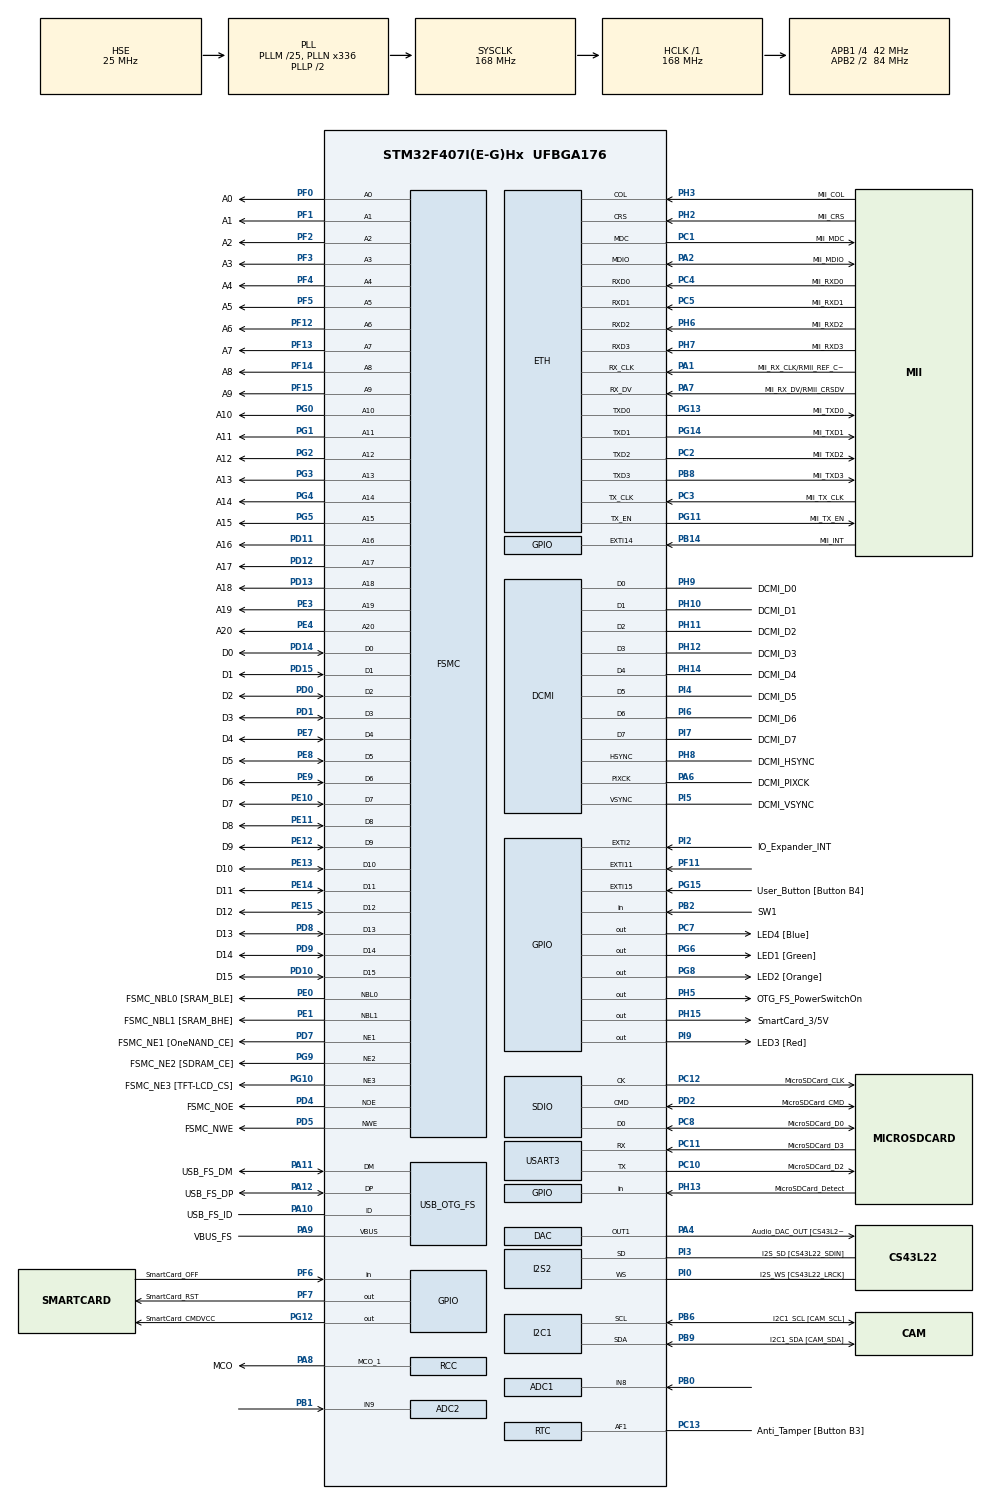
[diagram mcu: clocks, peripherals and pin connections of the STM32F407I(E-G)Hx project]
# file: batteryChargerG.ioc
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ADC1.Channel-0\#ChannelRegularConversion=ADC_CHANNEL_8
ADC1.Channel-4\#ChannelRegularConversion=ADC_CHANNEL_8
ADC1.ClockPrescaler=ADC_CLOCKPRESCALER_PCLK_DIV4
ADC1.ContinuousConvMode=ENABLE
ADC1.DMAContinuousRequests=ENABLE
ADC1.DataAlign=ADC_DATAALIGN_RIGHT
ADC1.DiscontinuousConvMode=DISABLE
ADC1.EOCSelection=EOC_SINGLE_CONV
ADC1.EnableAnalogWatchDog=false
ADC1.ExternalTrigConvEdge=ADC_EXTERNALTRIGCONVEDGE_NONE
ADC1.InjNumberOfConversion=0
ADC1.Mode=ADC_DUALMODE_REGSIMULT
ADC1.NbrOfConversion=1
ADC1.NbrOfConversionFlag=1
ADC1.Rank-0\#ChannelRegularConversion=1
ADC1.Rank-4\#ChannelRegularConversion=1
ADC1.Resolution=ADC_RESOLUTION12b
ADC1.SamplingTime-0\#ChannelRegularConversion=ADC_SAMPLETIME_15CYCLES
ADC1.SamplingTime-4\#ChannelRegularConversion=ADC_SAMPLETIME_15CYCLES
ADC1.ScanConvMode=DISABLE
ADC1.master=1
ADC2.Channel-4\#ChannelRegularConversion=ADC_CHANNEL_9
ADC2.ClockPrescaler=ADC_CLOCKPRESCALER_PCLK_DIV4
ADC2.ContinuousConvMode=ENABLE
ADC2.DMAAccessMode=ADC_DMAACCESSMODE_2
ADC2.DMAContinuousRequests=ENABLE
ADC2.DataAlign=ADC_DATAALIGN_RIGHT
ADC2.DiscontinuousConvMode=DISABLE
ADC2.EOCSelection=EOC_SINGLE_CONV
ADC2.EnableAnalogWatchDog=false
ADC2.Mode=ADC_DUALMODE_REGSIMULT
ADC2.NbrOfConversion=1
ADC2.NbrOfConversionFlag=1
ADC2.Rank-4\#ChannelRegularConversion=1
ADC2.Resolution=ADC_RESOLUTION12b
ADC2.SamplingTime-4\#ChannelRegularConversion=ADC_SAMPLETIME_15CYCLES
ADC2.ScanConvMode=DISABLE
DAC.DAC_Trigger=DAC_TRIGGER_T6_TRGO
Dma.ADC1.1.Channel=DMA_CHANNEL_0
Dma.ADC1.1.Direction=DMA_PERIPH_TO_MEMORY
Dma.ADC1.1.FIFOMode=DMA_FIFOMODE_DISABLE
Dma.ADC1.1.Instance=DMA2_Stream0
Dma.ADC1.1.MemDataAlignment=DMA_MDATAALIGN_WORD
Dma.ADC1.1.MemInc=DMA_MINC_ENABLE
Dma.ADC1.1.Mode=DMA_CIRCULAR
Dma.ADC1.1.PeriphDataAlignment=DMA_PDATAALIGN_WORD
Dma.ADC1.1.PeriphInc=DMA_PINC_DISABLE
Dma.ADC1.1.Priority=DMA_PRIORITY_LOW
Dma.DAC1.0.Channel=DMA_CHANNEL_7
Dma.DAC1.0.Direction=DMA_MEMORY_TO_PERIPH
Dma.DAC1.0.FIFOMode=DMA_FIFOMODE_DISABLE
Dma.DAC1.0.Instance=DMA1_Stream5
Dma.DAC1.0.MemDataAlignment=DMA_MDATAALIGN_HALFWORD
Dma.DAC1.0.MemInc=DMA_MINC_ENABLE
Dma.DAC1.0.Mode=DMA_CIRCULAR
Dma.DAC1.0.PeriphDataAlignment=DMA_PDATAALIGN_HALFWORD
Dma.DAC1.0.PeriphInc=DMA_PINC_DISABLE
Dma.DAC1.0.Priority=DMA_PRIORITY_LOW
Dma.Request0=DAC1
Dma.Request1=ADC1
FREERTOS.Tasks01=defaultTask,0,128,StartDefaultTask
LWIP.DEFAULT_ACCEPTMBOX_SIZE=2000
LWIP.DEFAULT_RAW_RECVMBOX_SIZE=2000
LWIP.DEFAULT_TCP_RECVMBOX_SIZE=2000
LWIP.DEFAULT_UDP_RECVMBOX_SIZE=2000
LWIP.LWIP_NETIF_LINK_CALLBACK=1
LWIP.TCPIP_MBOX_SIZE=5
LWIP.TCP_LISTEN_BACKLOG=1
Mcu.Family=STM32F4
Mcu.Name=STM32F407I(E-G)Hx
Mcu.Package=UFBGA176
NVIC.DMA1_Stream5_IRQn=true\:5\:0\:false
NVIC.DMA2_Stream0_IRQn=true\:5\:0\:false
NVIC.ETH_IRQn=true\:5\:0\:false
NVIC.PriorityGroup=NVIC_PRIORITYGROUP_4
PA0-WKUP.GPIO_Label=WAKEUP [Button B2]
PA0-WKUP.Mode=SYS-WakeUp
PA0-WKUP.Signal=SYS_WKUP
PA1.GPIO_Label=MII_RX_CLK/RMII_REF_CLK
PA1.GPIO_Mode=GPIO_MODE_AF_PP
PA1.GPIO_PuPd=GPIO_NOPULL
PA1.GPIO_Speed=GPIO_SPEED_LOW
PA1.Mode=MII
PA1.Signal=ETH_RX_CLK
PA10.GPIO_Label=USB_FS_ID
PA10.GPIO_Mode=GPIO_MODE_AF_PP
PA10.GPIO_PuPd=GPIO_NOPULL
PA10.GPIO_Speed=GPIO_SPEED_LOW
PA10.Mode=OTG/Dual_Role_Device
PA10.Signal=USB_OTG_FS_ID
PA11.GPIO_Label=USB_FS_DM
PA11.GPIO_Mode=GPIO_MODE_AF_PP
PA11.GPIO_PuPd=GPIO_NOPULL
PA11.GPIO_Speed=GPIO_SPEED_LOW
PA11.Mode=OTG/Dual_Role_Device
PA11.Signal=USB_OTG_FS_DM
PA12.GPIO_Label=USB_FS_DP
PA12.GPIO_Mode=GPIO_MODE_AF_PP
PA12.GPIO_PuPd=GPIO_NOPULL
PA12.GPIO_Speed=GPIO_SPEED_LOW
PA12.Mode=OTG/Dual_Role_Device
PA12.Signal=USB_OTG_FS_DP
PA13.GPIO_Label=TMS/SWDIO
PA13.Mode=Trace-Asynchronous_SW
PA13.Signal=SYS_JTMS-SWDIO
PA14.GPIO_Label=TCK/SWCLK
PA14.Mode=Trace-Asynchronous_SW
PA14.Signal=SYS_JTCK-SWCLK
PA15.GPIO_Label=TDI
PA15.Signal=SYS_JTDI
PA2.GPIO_Label=MII_MDIO
PA2.GPIO_Mode=GPIO_MODE_AF_PP
PA2.GPIO_PuPd=GPIO_NOPULL
PA2.GPIO_Speed=GPIO_SPEED_LOW
PA2.Mode=MII
PA2.Signal=ETH_MDIO
PA3.Signal=ADCx_IN3
PA4.GPIO_Label=Audio_DAC_OUT [CS43L22_AIN1]
PA4.GPIO_Mode=GPIO_MODE_ANALOG
PA4.GPIO_PuPd=GPIO_NOPULL
PA4.Signal=COMP_DAC1_group
PA5.GPIO_Label=ULPI_CLK
PA5.GPIO_Mode=GPIO_MODE_AF_PP
PA5.GPIO_PuPd=GPIO_NOPULL
PA5.GPIO_Speed=GPIO_SPEED_HIGH
PA5.Signal=USB_OTG_HS_ULPI_CK
PA6.GPIO_Label=DCMI_PIXCK
PA6.GPIO_Mode=GPIO_MODE_AF_PP
PA6.GPIO_PuPd=GPIO_NOPULL
PA6.GPIO_Speed=GPIO_SPEED_LOW
PA6.Mode=Slave_8_bits_External_Synchro
PA6.Signal=DCMI_PIXCK
PA7.GPIO_Label=MII_RX_DV/RMII_CRSDV
PA7.GPIO_Mode=GPIO_MODE_AF_PP
PA7.GPIO_PuPd=GPIO_NOPULL
PA7.GPIO_Speed=GPIO_SPEED_LOW
PA7.Mode=MII
PA7.Signal=ETH_RX_DV
PA8.GPIO_Label=MCO
PA8.GPIO_Mode=GPIO_MODE_AF_PP
PA8.GPIO_PuPd=GPIO_NOPULL
PA8.GPIO_Speed=GPIO_SPEED_LOW
PA8.Mode=Clock-out-1
PA8.Signal=RCC_MCO_1
PA9.GPIO_Label=VBUS_FS
PA9.GPIO_Mode=GPIO_MODE_INPUT
PA9.GPIO_PuPd=GPIO_NOPULL
PA9.Mode=Activate_VBUS
PA9.Signal=USB_OTG_FS_VBUS
PB0.Signal=ADCx_IN8
PB1.Signal=ADCx_IN9
PB10.GPIO_Label=ULPI_D3
PB10.GPIO_Mode=GPIO_MODE_AF_PP
PB10.GPIO_PuPd=GPIO_NOPULL
PB10.GPIO_Speed=GPIO_SPEED_HIGH
PB10.Signal=USB_OTG_HS_ULPI_D3
PB11.GPIO_Label=ULPI_D4
PB11.GPIO_Mode=GPIO_MODE_AF_PP
PB11.GPIO_PuPd=GPIO_NOPULL
PB11.GPIO_Speed=GPIO_SPEED_HIGH
PB11.Signal=USB_OTG_HS_ULPI_D4
PB12.GPIO_Label=ULPI_D5
PB12.GPIO_Mode=GPIO_MODE_AF_PP
PB12.GPIO_PuPd=GPIO_NOPULL
PB12.GPIO_Speed=GPIO_SPEED_HIGH
PB12.Signal=USB_OTG_HS_ULPI_D5
PB13.GPIO_Label=ULPI_D6
PB13.GPIO_Mode=GPIO_MODE_AF_PP
PB13.GPIO_PuPd=GPIO_NOPULL
PB13.GPIO_Speed=GPIO_SPEED_HIGH
PB13.Signal=USB_OTG_HS_ULPI_D6
PB14.GPIO_Label=MII_INT
PB14.GPIO_ModeDefaultEXTI=GPIO_MODE_EVT_RISING
PB14.GPIO_PuPd=GPIO_NOPULL
PB14.Signal=GPXTI14
PB2.GPIO_Label=SW1
PB2.GPIO_Mode=GPIO_MODE_INPUT
PB2.GPIO_PuPd=GPIO_NOPULL
PB2.Signal=GPIO_Input
PB3.GPIO_Label=TDO/SWO
PB3.Mode=Trace-Asynchronous_SW
PB3.Signal=SYS_JTDO-SWO
PB4.GPIO_Label=TRST
PB4.Signal=SYS_JTRST
PB5.GPIO_Label=ULPI_D7
PB5.GPIO_Mode=GPIO_MODE_AF_PP
PB5.GPIO_PuPd=GPIO_NOPULL
PB5.GPIO_Speed=GPIO_SPEED_HIGH
PB5.Signal=USB_OTG_HS_ULPI_D7
PB6.GPIO_Label=I2C1_SCL [CAM_SCL]
PB6.GPIO_Mode=GPIO_MODE_AF_OD
PB6.GPIO_PuPd=GPIO_NOPULL
PB6.GPIO_Speed=GPIO_SPEED_LOW
PB6.Mode=I2C
PB6.Signal=I2C1_SCL
PB7.GPIO_Label=FSMC_NL [OneNAND_AVD]
PB7.GPIO_Mode=GPIO_MODE_AF_PP
PB7.GPIO_PuPd=GPIO_NOPULL
PB7.GPIO_Speed=GPIO_SPEED_LOW
PB7.Signal=FSMC_NL
PB8.GPIO_Label=MII_TXD3
PB8.GPIO_Mode=GPIO_MODE_AF_PP
PB8.GPIO_PuPd=GPIO_NOPULL
PB8.GPIO_Speed=GPIO_SPEED_LOW
PB8.Mode=MII
PB8.Signal=ETH_TXD3
PB9.GPIO_Label=I2C1_SDA [CAM_SDA]
PB9.GPIO_Mode=GPIO_MODE_AF_OD
PB9.GPIO_PuPd=GPIO_NOPULL
PB9.GPIO_Speed=GPIO_SPEED_LOW
PB9.Mode=I2C
PB9.Signal=I2C1_SDA
PC0.GPIO_Label=ULPI_STP
PC0.GPIO_Mode=GPIO_MODE_AF_PP
PC0.GPIO_PuPd=GPIO_NOPULL
PC0.GPIO_Speed=GPIO_SPEED_HIGH
PC0.Signal=USB_OTG_HS_ULPI_STP
PC1.GPIO_Label=MII_MDC
PC1.GPIO_Mode=GPIO_MODE_AF_PP
PC1.GPIO_PuPd=GPIO_NOPULL
PC1.GPIO_Speed=GPIO_SPEED_LOW
PC1.Mode=MII
PC1.Signal=ETH_MDC
PC10.GPIO_Label=MicroSDCard_D2
PC10.GPIO_Mode=GPIO_MODE_AF_PP
PC10.GPIO_PuPd=GPIO_NOPULL
PC10.GPIO_Speed=GPIO_SPEED_LOW
PC10.Mode=Asynchronous
PC10.Signal=USART3_TX
PC11.GPIO_Label=MicroSDCard_D3
PC11.GPIO_Mode=GPIO_MODE_AF_PP
PC11.GPIO_PuPd=GPIO_NOPULL
PC11.GPIO_Speed=GPIO_SPEED_LOW
PC11.Mode=Asynchronous
PC11.Signal=USART3_RX
PC12.GPIO_Label=MicroSDCard_CLK
PC12.GPIO_Mode=GPIO_MODE_AF_PP
PC12.GPIO_PuPd=GPIO_NOPULL
PC12.GPIO_Speed=GPIO_SPEED_LOW
PC12.Mode=SD_1_bit
PC12.Signal=SDIO_CK
PC13-ANTI_TAMP.GPIO_Label=Anti_Tamper [Button B3]
PC13-ANTI_TAMP.Mode=Alarm A
PC13-ANTI_TAMP.Signal=RTC_AF1
PC14-OSC32_IN.GPIO_Label=PC14-OSC32_IN
PC14-OSC32_IN.Mode=LSE-External-Oscillator
PC14-OSC32_IN.Signal=RCC_OSC32_IN
PC15-OSC32_OUT.GPIO_Label=PC15-OSC32_OUT
PC15-OSC32_OUT.Mode=LSE-External-Oscillator
PC15-OSC32_OUT.Signal=RCC_OSC32_OUT
PC2.GPIO_Label=MII_TXD2
PC2.GPIO_Mode=GPIO_MODE_AF_PP
PC2.GPIO_PuPd=GPIO_NOPULL
PC2.GPIO_Speed=GPIO_SPEED_LOW
PC2.Mode=MII
PC2.Signal=ETH_TXD2
PC3.GPIO_Label=MII_TX_CLK
PC3.GPIO_Mode=GPIO_MODE_AF_PP
PC3.GPIO_PuPd=GPIO_NOPULL
PC3.GPIO_Speed=GPIO_SPEED_LOW
PC3.Mode=MII
PC3.Signal=ETH_TX_CLK
PC4.GPIO_Label=MII_RXD0
PC4.GPIO_Mode=GPIO_MODE_AF_PP
PC4.GPIO_PuPd=GPIO_NOPULL
PC4.GPIO_Speed=GPIO_SPEED_LOW
PC4.Mode=MII
PC4.Signal=ETH_RXD0
PC5.GPIO_Label=MII_RXD1
PC5.GPIO_Mode=GPIO_MODE_AF_PP
PC5.GPIO_PuPd=GPIO_NOPULL
PC5.GPIO_Speed=GPIO_SPEED_LOW
PC5.Mode=MII
PC5.Signal=ETH_RXD1
PC7.GPIO_Label=LED4 [Blue]
PC7.GPIO_Mode=GPIO_MODE_OUTPUT_PP
PC7.GPIO_ModeDefaultOutputPP=GPIO_MODE_OUTPUT_PP
PC7.GPIO_PuPd=GPIO_NOPULL
PC7.GPIO_Speed=GPIO_SPEED_LOW
PC7.Signal=GPIO_Output
PC8.GPIO_Label=MicroSDCard_D0
PC8.GPIO_Mode=GPIO_MODE_AF_PP
PC8.GPIO_PuPd=GPIO_NOPULL
PC8.GPIO_Speed=GPIO_SPEED_LOW
PC8.Mode=SD_1_bit
PC8.Signal=SDIO_D0
PC9.GPIO_Label=MicroSDCard_D1
PC9.GPIO_Mode=GPIO_MODE_AF_PP
PC9.GPIO_PuPd=GPIO_NOPULL
PC9.GPIO_Speed=GPIO_SPEED_LOW
PC9.Signal=SDIO_D1
PD0.GPIO_Label=D2
PD0.GPIO_Mode=GPIO_MODE_AF_PP
PD0.GPIO_PuPd=GPIO_NOPULL
PD0.GPIO_Speed=GPIO_SPEED_LOW
PD0.Signal=FSMC_D2_DA2
PD1.GPIO_Label=D3
PD1.GPIO_Mode=GPIO_MODE_AF_PP
PD1.GPIO_PuPd=GPIO_NOPULL
PD1.GPIO_Speed=GPIO_SPEED_LOW
PD1.Signal=FSMC_D3_DA3
PD10.GPIO_Label=D15
PD10.GPIO_Mode=GPIO_MODE_AF_PP
PD10.GPIO_PuPd=GPIO_NOPULL
PD10.GPIO_Speed=GPIO_SPEED_LOW
PD10.Signal=FSMC_D15_DA15
PD11.GPIO_Label=A16
PD11.GPIO_Mode=GPIO_MODE_AF_PP
PD11.GPIO_PuPd=GPIO_NOPULL
PD11.GPIO_Speed=GPIO_SPEED_LOW
PD11.Signal=FSMC_A16_CLE
PD12.GPIO_Label=A17
PD12.GPIO_Mode=GPIO_MODE_AF_PP
PD12.GPIO_PuPd=GPIO_NOPULL
PD12.GPIO_Speed=GPIO_SPEED_LOW
PD12.Signal=FSMC_A17_ALE
PD13.GPIO_Label=A18
PD13.GPIO_Mode=GPIO_MODE_AF_PP
PD13.GPIO_PuPd=GPIO_NOPULL
PD13.GPIO_Speed=GPIO_SPEED_LOW
PD13.Signal=FSMC_A18
PD14.GPIO_Label=D0
PD14.GPIO_Mode=GPIO_MODE_AF_PP
PD14.GPIO_PuPd=GPIO_NOPULL
PD14.GPIO_Speed=GPIO_SPEED_LOW
PD14.Signal=FSMC_D0_DA0
PD15.GPIO_Label=D1
PD15.GPIO_Mode=GPIO_MODE_AF_PP
PD15.GPIO_PuPd=GPIO_NOPULL
PD15.GPIO_Speed=GPIO_SPEED_LOW
PD15.Signal=FSMC_D1_DA1
PD2.GPIO_Label=MicroSDCard_CMD
PD2.GPIO_Mode=GPIO_MODE_AF_PP
PD2.GPIO_PuPd=GPIO_NOPULL
PD2.GPIO_Speed=GPIO_SPEED_LOW
PD2.Mode=SD_1_bit
PD2.Signal=SDIO_CMD
PD3.GPIO_Label=FSMC_CLK [OneNAND_CLK]
PD3.GPIO_Mode=GPIO_MODE_AF_PP
PD3.GPIO_PuPd=GPIO_NOPULL
PD3.GPIO_Speed=GPIO_SPEED_LOW
PD3.Signal=FSMC_CLK
PD4.GPIO_Label=FSMC_NOE
PD4.GPIO_Mode=GPIO_MODE_AF_PP
PD4.GPIO_PuPd=GPIO_NOPULL
PD4.GPIO_Speed=GPIO_SPEED_LOW
PD4.Signal=FSMC_NOE
PD5.GPIO_Label=FSMC_NWE
PD5.GPIO_Mode=GPIO_MODE_AF_PP
PD5.GPIO_PuPd=GPIO_NOPULL
PD5.GPIO_Speed=GPIO_SPEED_LOW
PD5.Signal=FSMC_NWE
PD6.GPIO_Label=FSMC_NWAIT [OneNAND_RDY]
PD6.GPIO_Mode=GPIO_MODE_AF_PP
PD6.GPIO_PuPd=GPIO_NOPULL
PD6.GPIO_Speed=GPIO_SPEED_LOW
PD6.Signal=FSMC_NWAIT
PD7.GPIO_Label=FSMC_NE1 [OneNAND_CE]
PD7.GPIO_Mode=GPIO_MODE_AF_PP
PD7.GPIO_PuPd=GPIO_NOPULL
PD7.GPIO_Speed=GPIO_SPEED_LOW
PD7.Mode=NorPsramChipSelect1_1
PD7.Signal=FSMC_NE1
PD8.GPIO_Label=D13
PD8.GPIO_Mode=GPIO_MODE_AF_PP
PD8.GPIO_PuPd=GPIO_NOPULL
PD8.GPIO_Speed=GPIO_SPEED_LOW
PD8.Signal=FSMC_D13_DA13
PD9.GPIO_Label=D14
PD9.GPIO_Mode=GPIO_MODE_AF_PP
PD9.GPIO_PuPd=GPIO_NOPULL
PD9.GPIO_Speed=GPIO_SPEED_LOW
PD9.Signal=FSMC_D14_DA14
PE0.GPIO_Label=FSMC_NBL0 [SRAM_BLE]
PE0.GPIO_Mode=GPIO_MODE_AF_PP
PE0.GPIO_PuPd=GPIO_NOPULL
PE0.GPIO_Speed=GPIO_SPEED_LOW
PE0.Signal=FSMC_NBL0
PE1.GPIO_Label=FSMC_NBL1 [SRAM_BHE]
PE1.GPIO_Mode=GPIO_MODE_AF_PP
PE1.GPIO_PuPd=GPIO_NOPULL
PE1.GPIO_Speed=GPIO_SPEED_LOW
PE1.Signal=FSMC_NBL1
PE10.GPIO_Label=D7
PE10.GPIO_Mode=GPIO_MODE_AF_PP
PE10.GPIO_PuPd=GPIO_NOPULL
PE10.GPIO_Speed=GPIO_SPEED_LOW
PE10.Signal=FSMC_D7_DA7
PE11.GPIO_Label=D8
PE11.GPIO_Mode=GPIO_MODE_AF_PP
PE11.GPIO_PuPd=GPIO_NOPULL
PE11.GPIO_Speed=GPIO_SPEED_LOW
PE11.Signal=FSMC_D8_DA8
PE12.GPIO_Label=D9
PE12.GPIO_Mode=GPIO_MODE_AF_PP
PE12.GPIO_PuPd=GPIO_NOPULL
PE12.GPIO_Speed=GPIO_SPEED_LOW
PE12.Signal=FSMC_D9_DA9
PE13.GPIO_Label=D10
PE13.GPIO_Mode=GPIO_MODE_AF_PP
PE13.GPIO_PuPd=GPIO_NOPULL
PE13.GPIO_Speed=GPIO_SPEED_LOW
PE13.Signal=FSMC_D10_DA10
PE14.GPIO_Label=D11
PE14.GPIO_Mode=GPIO_MODE_AF_PP
PE14.GPIO_PuPd=GPIO_NOPULL
PE14.GPIO_Speed=GPIO_SPEED_LOW
PE14.Signal=FSMC_D11_DA11
PE15.GPIO_Label=D12
PE15.GPIO_Mode=GPIO_MODE_AF_PP
PE15.GPIO_PuPd=GPIO_NOPULL
PE15.GPIO_Speed=GPIO_SPEED_LOW
PE15.Signal=FSMC_D12_DA12
PE2.GPIO_Label=TRACE_CLK
PE2.Signal=SYS_TRACECLK
PE3.GPIO_Label=A19
PE3.GPIO_Mode=GPIO_MODE_AF_PP
PE3.GPIO_PuPd=GPIO_NOPULL
PE3.GPIO_Speed=GPIO_SPEED_LOW
PE3.Signal=FSMC_A19
PE4.GPIO_Label=A20
PE4.GPIO_Mode=GPIO_MODE_AF_PP
PE4.GPIO_PuPd=GPIO_NOPULL
PE4.GPIO_Speed=GPIO_SPEED_LOW
PE4.Signal=FSMC_A20
PE5.GPIO_Label=TRACE_D2
PE5.Signal=SYS_TRACED2
PE6.GPIO_Label=TRACE_D3
PE6.Signal=SYS_TRACED3
PE7.GPIO_Label=D4
PE7.GPIO_Mode=GPIO_MODE_AF_PP
PE7.GPIO_PuPd=GPIO_NOPULL
PE7.GPIO_Speed=GPIO_SPEED_LOW
PE7.Signal=FSMC_D4_DA4
PE8.GPIO_Label=D5
PE8.GPIO_Mode=GPIO_MODE_AF_PP
PE8.GPIO_PuPd=GPIO_NOPULL
PE8.GPIO_Speed=GPIO_SPEED_LOW
PE8.Signal=FSMC_D5_DA5
PE9.GPIO_Label=D6
PE9.GPIO_Mode=GPIO_MODE_AF_PP
PE9.GPIO_PuPd=GPIO_NOPULL
PE9.GPIO_Speed=GPIO_SPEED_LOW
PE9.Signal=FSMC_D6_DA6
PF0.GPIO_Label=A0
PF0.GPIO_Mode=GPIO_MODE_AF_PP
PF0.GPIO_PuPd=GPIO_NOPULL
PF0.GPIO_Speed=GPIO_SPEED_LOW
PF0.Signal=FSMC_A0
PF1.GPIO_Label=A1
PF1.GPIO_Mode=GPIO_MODE_AF_PP
PF1.GPIO_PuPd=GPIO_NOPULL
PF1.GPIO_Speed=GPIO_SPEED_LOW
PF1.Signal=FSMC_A1
PF10.GPIO_Label=Audio_IN [TS472_OUT+]
PF10.GPIO_Mode=GPIO_MODE_ANALOG
PF10.GPIO_PuPd=GPIO_NOPULL
PF10.Signal=ADC3_IN8
PF11.Signal=GPXTI11
PF12.GPIO_Label=A6
PF12.GPIO_Mode=GPIO_MODE_AF_PP
PF12.GPIO_PuPd=GPIO_NOPULL
PF12.GPIO_Speed=GPIO_SPEED_LOW
PF12.Signal=FSMC_A6
PF13.GPIO_Label=A7
PF13.GPIO_Mode=GPIO_MODE_AF_PP
PF13.GPIO_PuPd=GPIO_NOPULL
PF13.GPIO_Speed=GPIO_SPEED_LOW
PF13.Signal=FSMC_A7
PF14.GPIO_Label=A8
PF14.GPIO_Mode=GPIO_MODE_AF_PP
PF14.GPIO_PuPd=GPIO_NOPULL
PF14.GPIO_Speed=GPIO_SPEED_LOW
PF14.Signal=FSMC_A8
PF15.GPIO_Label=A9
PF15.GPIO_Mode=GPIO_MODE_AF_PP
PF15.GPIO_PuPd=GPIO_NOPULL
PF15.GPIO_Speed=GPIO_SPEED_LOW
PF15.Signal=FSMC_A9
PF2.GPIO_Label=A2
PF2.GPIO_Mode=GPIO_MODE_AF_PP
PF2.GPIO_PuPd=GPIO_NOPULL
PF2.GPIO_Speed=GPIO_SPEED_LOW
PF2.Signal=FSMC_A2
PF3.GPIO_Label=A3
PF3.GPIO_Mode=GPIO_MODE_AF_PP
PF3.GPIO_PuPd=GPIO_NOPULL
PF3.GPIO_Speed=GPIO_SPEED_LOW
PF3.Signal=FSMC_A3
PF4.GPIO_Label=A4
PF4.GPIO_Mode=GPIO_MODE_AF_PP
PF4.GPIO_PuPd=GPIO_NOPULL
PF4.GPIO_Speed=GPIO_SPEED_LOW
PF4.Signal=FSMC_A4
PF5.GPIO_Label=A5
PF5.GPIO_Mode=GPIO_MODE_AF_PP
PF5.GPIO_PuPd=GPIO_NOPULL
PF5.GPIO_Speed=GPIO_SPEED_LOW
PF5.Signal=FSMC_A5
PF6.GPIO_Label=SmartCard_OFF
PF6.GPIO_Mode=GPIO_MODE_INPUT
PF6.GPIO_PuPd=GPIO_NOPULL
PF6.Signal=GPIO_Input
PF7.GPIO_Label=SmartCard_RST
PF7.GPIO_Mode=GPIO_MODE_OUTPUT_PP
PF7.GPIO_ModeDefaultOutputPP=GPIO_MODE_OUTPUT_PP
PF7.GPIO_PuPd=GPIO_NOPULL
PF7.GPIO_Speed=GPIO_SPEED_LOW
PF7.Signal=GPIO_Output
PF9.GPIO_Label=Potentiometer [RV1]
PF9.GPIO_Mode=GPIO_MODE_ANALOG
PF9.GPIO_PuPd=GPIO_NOPULL
PF9.Signal=ADC3_IN7
PG0.GPIO_Label=A10
PG0.GPIO_Mode=GPIO_MODE_AF_PP
PG0.GPIO_PuPd=GPIO_NOPULL
PG0.GPIO_Speed=GPIO_SPEED_LOW
PG0.Signal=FSMC_A10
PG1.GPIO_Label=A11
PG1.GPIO_Mode=GPIO_MODE_AF_PP
PG1.GPIO_PuPd=GPIO_NOPULL
PG1.GPIO_Speed=GPIO_SPEED_LOW
PG1.Signal=FSMC_A11
PG10.GPIO_Label=FSMC_NE3 [TFT-LCD_CS]
PG10.GPIO_Mode=GPIO_MODE_AF_PP
PG10.GPIO_PuPd=GPIO_NOPULL
PG10.GPIO_Speed=GPIO_SPEED_LOW
PG10.Mode=NorPsramChipSelect3_3
PG10.Signal=FSMC_NE3
PG11.GPIO_Label=MII_TX_EN
PG11.GPIO_Mode=GPIO_MODE_AF_PP
PG11.GPIO_PuPd=GPIO_NOPULL
PG11.GPIO_Speed=GPIO_SPEED_LOW
PG11.Mode=MII
PG11.Signal=ETH_TX_EN
PG12.GPIO_Label=SmartCard_CMDVCC
PG12.GPIO_Mode=GPIO_MODE_OUTPUT_PP
PG12.GPIO_ModeDefaultOutputPP=GPIO_MODE_OUTPUT_PP
PG12.GPIO_PuPd=GPIO_NOPULL
PG12.GPIO_Speed=GPIO_SPEED_LOW
PG12.Signal=GPIO_Output
PG13.GPIO_Label=MII_TXD0
PG13.GPIO_Mode=GPIO_MODE_AF_PP
PG13.GPIO_PuPd=GPIO_NOPULL
PG13.GPIO_Speed=GPIO_SPEED_LOW
PG13.Mode=MII
PG13.Signal=ETH_TXD0
PG14.GPIO_Label=MII_TXD1
PG14.GPIO_Mode=GPIO_MODE_AF_PP
PG14.GPIO_PuPd=GPIO_NOPULL
PG14.GPIO_Speed=GPIO_SPEED_LOW
PG14.Mode=MII
PG14.Signal=ETH_TXD1
PG15.GPIO_Label=User_Button [Button B4]
PG15.GPIO_ModeDefaultEXTI=GPIO_MODE_EVT_RISING
PG15.GPIO_PuPd=GPIO_NOPULL
PG15.Signal=GPXTI15
PG2.GPIO_Label=A12
PG2.GPIO_Mode=GPIO_MODE_AF_PP
PG2.GPIO_PuPd=GPIO_NOPULL
PG2.GPIO_Speed=GPIO_SPEED_LOW
PG2.Signal=FSMC_A12
PG3.GPIO_Label=A13
PG3.GPIO_Mode=GPIO_MODE_AF_PP
PG3.GPIO_PuPd=GPIO_NOPULL
PG3.GPIO_Speed=GPIO_SPEED_LOW
PG3.Signal=FSMC_A13
PG4.GPIO_Label=A14
PG4.GPIO_Mode=GPIO_MODE_AF_PP
PG4.GPIO_PuPd=GPIO_NOPULL
PG4.GPIO_Speed=GPIO_SPEED_LOW
PG4.Signal=FSMC_A14
PG5.GPIO_Label=A15
PG5.GPIO_Mode=GPIO_MODE_AF_PP
PG5.GPIO_PuPd=GPIO_NOPULL
PG5.GPIO_Speed=GPIO_SPEED_LOW
PG5.Signal=FSMC_A15
PG6.GPIO_Label=LED1 [Green]
PG6.GPIO_Mode=GPIO_MODE_OUTPUT_PP
PG6.GPIO_ModeDefaultOutputPP=GPIO_MODE_OUTPUT_PP
PG6.GPIO_PuPd=GPIO_NOPULL
PG6.GPIO_Speed=GPIO_SPEED_LOW
PG6.Signal=GPIO_Output
PG7.GPIO_Label=SmartCard_CLK
PG7.GPIO_Mode=GPIO_MODE_AF_PP
PG7.GPIO_PuPd=GPIO_NOPULL
PG7.GPIO_Speed=GPIO_SPEED_LOW
PG7.Signal=USART6_CK
PG8.GPIO_Label=LED2 [Orange]
PG8.GPIO_Mode=GPIO_MODE_OUTPUT_PP
PG8.GPIO_ModeDefaultOutputPP=GPIO_MODE_OUTPUT_PP
PG8.GPIO_PuPd=GPIO_NOPULL
PG8.GPIO_Speed=GPIO_SPEED_LOW
PG8.Signal=GPIO_Output
PG9.GPIO_Label=FSMC_NE2 [SDRAM_CE]
PG9.GPIO_Mode=GPIO_MODE_AF_PP
PG9.GPIO_PuPd=GPIO_NOPULL
PG9.GPIO_Speed=GPIO_SPEED_LOW
PG9.Mode=NorPsramChipSelect2_2
PG9.Signal=FSMC_NE2
PH0-OSC_IN.GPIO_Label=PH0-OSC_IN
PH0-OSC_IN.Mode=HSE-External-Oscillator
PH0-OSC_IN.Signal=RCC_OSC_IN
PH1-OSC_OUT.GPIO_Label=PH1-OSC_OUT
PH1-OSC_OUT.Mode=HSE-External-Oscillator
PH1-OSC_OUT.Signal=RCC_OSC_OUT
PH10.GPIO_Label=DCMI_D1
PH10.GPIO_Mode=GPIO_MODE_AF_PP
PH10.GPIO_PuPd=GPIO_NOPULL
PH10.GPIO_Speed=GPIO_SPEED_LOW
PH10.Mode=Slave_8_bits_External_Synchro
PH10.Signal=DCMI_D1
PH11.GPIO_Label=DCMI_D2
PH11.GPIO_Mode=GPIO_MODE_AF_PP
PH11.GPIO_PuPd=GPIO_NOPULL
PH11.GPIO_Speed=GPIO_SPEED_LOW
PH11.Mode=Slave_8_bits_External_Synchro
PH11.Signal=DCMI_D2
PH12.GPIO_Label=DCMI_D3
PH12.GPIO_Mode=GPIO_MODE_AF_PP
PH12.GPIO_PuPd=GPIO_NOPULL
PH12.GPIO_Speed=GPIO_SPEED_LOW
PH12.Mode=Slave_8_bits_External_Synchro
PH12.Signal=DCMI_D3
PH13.GPIO_Label=MicroSDCard_Detect
PH13.GPIO_Mode=GPIO_MODE_INPUT
PH13.GPIO_PuPd=GPIO_PULLUP
PH13.Signal=GPIO_Input
PH14.GPIO_Label=DCMI_D4
PH14.GPIO_Mode=GPIO_MODE_AF_PP
PH14.GPIO_PuPd=GPIO_NOPULL
PH14.GPIO_Speed=GPIO_SPEED_LOW
PH14.Mode=Slave_8_bits_External_Synchro
PH14.Signal=DCMI_D4
PH15.GPIO_Label=SmartCard_3/5V
PH15.GPIO_Mode=GPIO_MODE_OUTPUT_PP
PH15.GPIO_ModeDefaultOutputPP=GPIO_MODE_OUTPUT_PP
PH15.GPIO_PuPd=GPIO_NOPULL
PH15.GPIO_Speed=GPIO_SPEED_LOW
PH15.Signal=GPIO_Output
PH2.GPIO_Label=MII_CRS
PH2.GPIO_Mode=GPIO_MODE_AF_PP
PH2.GPIO_PuPd=GPIO_NOPULL
PH2.GPIO_Speed=GPIO_SPEED_LOW
PH2.Mode=MII
PH2.Signal=ETH_CRS
PH3.GPIO_Label=MII_COL
PH3.GPIO_Mode=GPIO_MODE_AF_PP
PH3.GPIO_PuPd=GPIO_NOPULL
PH3.GPIO_Speed=GPIO_SPEED_LOW
PH3.Mode=MII
PH3.Signal=ETH_COL
PH4.GPIO_Label=ULPI_NXT
PH4.GPIO_Mode=GPIO_MODE_AF_PP
PH4.GPIO_PuPd=GPIO_NOPULL
PH4.GPIO_Speed=GPIO_SPEED_HIGH
PH4.Signal=USB_OTG_HS_ULPI_NXT
PH5.GPIO_Label=OTG_FS_PowerSwitchOn
PH5.GPIO_Mode=GPIO_MODE_OUTPUT_PP
PH5.GPIO_ModeDefaultOutputPP=GPIO_MODE_OUTPUT_PP
PH5.GPIO_PuPd=GPIO_NOPULL
PH5.GPIO_Speed=GPIO_SPEED_LOW
PH5.Signal=GPIO_Output
PH6.GPIO_Label=MII_RXD2
PH6.GPIO_Mode=GPIO_MODE_AF_PP
PH6.GPIO_PuPd=GPIO_NOPULL
PH6.GPIO_Speed=GPIO_SPEED_LOW
PH6.Mode=MII
PH6.Signal=ETH_RXD2
PH7.GPIO_Label=MII_RXD3
PH7.GPIO_Mode=GPIO_MODE_AF_PP
PH7.GPIO_PuPd=GPIO_NOPULL
PH7.GPIO_Speed=GPIO_SPEED_LOW
PH7.Mode=MII
PH7.Signal=ETH_RXD3
PH8.GPIO_Label=DCMI_HSYNC
PH8.GPIO_Mode=GPIO_MODE_AF_PP
PH8.GPIO_PuPd=GPIO_NOPULL
PH8.GPIO_Speed=GPIO_SPEED_LOW
PH8.Mode=Slave_8_bits_External_Synchro
PH8.Signal=DCMI_HSYNC
PH9.GPIO_Label=DCMI_D0
PH9.GPIO_Mode=GPIO_MODE_AF_PP
PH9.GPIO_PuPd=GPIO_NOPULL
PH9.GPIO_Speed=GPIO_SPEED_LOW
PH9.Mode=Slave_8_bits_External_Synchro
PH9.Signal=DCMI_D0
PI0.GPIO_Label=I2S_WS [CS43L22_LRCK]
PI0.GPIO_Mode=GPIO_MODE_AF_PP
PI0.GPIO_PuPd=GPIO_NOPULL
PI0.GPIO_Speed=GPIO_SPEED_LOW
PI0.Mode=Half_Duplex_Master
PI0.Signal=I2S2_WS
PI10.GPIO_Label=MII_RX_ER
PI10.GPIO_Mode=GPIO_MODE_AF_PP
PI10.GPIO_PuPd=GPIO_NOPULL
PI10.GPIO_Speed=GPIO_SPEED_LOW
PI10.Signal=ETH_RX_ER
PI11.GPIO_Label=ULPI_DIR
PI11.GPIO_Mode=GPIO_MODE_AF_PP
PI11.GPIO_PuPd=GPIO_NOPULL
PI11.GPIO_Speed=GPIO_SPEED_HIGH
PI11.Signal=USB_OTG_HS_ULPI_DIR
PI2.GPIO_Label=IO_Expander_INT
PI2.GPIO_ModeDefaultEXTI=GPIO_MODE_EVT_RISING
PI2.GPIO_PuPd=GPIO_NOPULL
PI2.Signal=GPXTI2
PI3.GPIO_Label=I2S_SD [CS43L22_SDIN]
PI3.GPIO_Mode=GPIO_MODE_AF_PP
PI3.GPIO_PuPd=GPIO_NOPULL
PI3.GPIO_Speed=GPIO_SPEED_LOW
PI3.Mode=Half_Duplex_Master
PI3.Signal=I2S2_SD
PI4.GPIO_Label=DCMI_D5
PI4.GPIO_Mode=GPIO_MODE_AF_PP
PI4.GPIO_PuPd=GPIO_NOPULL
PI4.GPIO_Speed=GPIO_SPEED_LOW
PI4.Mode=Slave_8_bits_External_Synchro
PI4.Signal=DCMI_D5
PI5.GPIO_Label=DCMI_VSYNC
PI5.GPIO_Mode=GPIO_MODE_AF_PP
PI5.GPIO_PuPd=GPIO_NOPULL
PI5.GPIO_Speed=GPIO_SPEED_LOW
PI5.Mode=Slave_8_bits_External_Synchro
PI5.Signal=DCMI_VSYNC
PI6.GPIO_Label=DCMI_D6
PI6.GPIO_Mode=GPIO_MODE_AF_PP
PI6.GPIO_PuPd=GPIO_NOPULL
PI6.GPIO_Speed=GPIO_SPEED_LOW
PI6.Mode=Slave_8_bits_External_Synchro
PI6.Signal=DCMI_D6
PI7.GPIO_Label=DCMI_D7
PI7.GPIO_Mode=GPIO_MODE_AF_PP
PI7.GPIO_PuPd=GPIO_NOPULL
PI7.GPIO_Speed=GPIO_SPEED_LOW
PI7.Mode=Slave_8_bits_External_Synchro
PI7.Signal=DCMI_D7
PI9.GPIO_Label=LED3 [Red]
PI9.GPIO_Mode=GPIO_MODE_OUTPUT_PP
PI9.GPIO_ModeDefaultOutputPP=GPIO_MODE_OUTPUT_PP
PI9.GPIO_PuPd=GPIO_NOPULL
PI9.GPIO_Speed=GPIO_SPEED_LOW
PI9.Signal=GPIO_Output
ProjectManager.TargetToolchain=SW4STM32
RCC.48MHZClocksFreq_Value=48000000
RCC.AHBFreq_Value=168000000
RCC.APB1CLKDivider=RCC_HCLK_DIV4
RCC.APB1Freq_Value=42000000
RCC.APB1TimFreq_Value=84000000
RCC.APB2CLKDivider=RCC_HCLK_DIV2
RCC.APB2Freq_Value=84000000
RCC.APB2TimFreq_Value=168000000
RCC.CortexFreq_Value=168000000
RCC.HCLKFreq_Value=168000000
RCC.HSE_VALUE=25000000
RCC.HSI_VALUE=16000000
RCC.PLLM=25
RCC.PLLN=336
RCC.PLLQ=7
RCC.RCC_MCO1Source=RCC_MCO1SOURCE_HSE
RCC.SYSCLKFreq_VALUE=168000000
RCC.SYSCLKSource=RCC_SYSCLKSOURCE_PLLCLK
RCC.VCOOutputFreq_Value=336000000
SDIO.BusWide=SDIO_BUS_WIDE_1B
SDIO.BusWide-SD_1_bit=SDIO_BUS_WIDE_1B
SH.ADCx_IN3.0=ADC1_IN3
SH.ADCx_IN8.0=ADC1_IN8,IN8
SH.ADCx_IN9.0=ADC2_IN9,IN9
SH.COMP_DAC1_group.0=DAC_OUT1,DAC_OUT1
SH.FSMC_A0.0=FSMC_A0,21b-a1
SH.FSMC_A0.1=FSMC_A0,21b-a2
SH.FSMC_A0.2=FSMC_A0,21b-a3
SH.FSMC_A1.0=FSMC_A1,21b-a1
SH.FSMC_A1.1=FSMC_A1,21b-a2
SH.FSMC_A1.2=FSMC_A1,21b-a3
SH.FSMC_A10.0=FSMC_A10,21b-a1
SH.FSMC_A10.1=FSMC_A10,21b-a2
SH.FSMC_A10.2=FSMC_A10,21b-a3
SH.FSMC_A11.0=FSMC_A11,21b-a1
SH.FSMC_A11.1=FSMC_A11,21b-a2
SH.FSMC_A11.2=FSMC_A11,21b-a3
SH.FSMC_A12.0=FSMC_A12,21b-a1
SH.FSMC_A12.1=FSMC_A12,21b-a2
SH.FSMC_A12.2=FSMC_A12,21b-a3
SH.FSMC_A13.0=FSMC_A13,21b-a1
SH.FSMC_A13.1=FSMC_A13,21b-a2
SH.FSMC_A13.2=FSMC_A13,21b-a3
SH.FSMC_A14.0=FSMC_A14,21b-a1
SH.FSMC_A14.1=FSMC_A14,21b-a2
SH.FSMC_A14.2=FSMC_A14,21b-a3
SH.FSMC_A15.0=FSMC_A15,21b-a1
SH.FSMC_A15.1=FSMC_A15,21b-a2
SH.FSMC_A15.2=FSMC_A15,21b-a3
SH.FSMC_A16_CLE.0=FSMC_A16,21b-a1
SH.FSMC_A16_CLE.1=FSMC_A16,21b-a2
SH.FSMC_A16_CLE.2=FSMC_A16,21b-a3
SH.FSMC_A17_ALE.0=FSMC_A17,21b-a1
SH.FSMC_A17_ALE.1=FSMC_A17,21b-a2
SH.FSMC_A17_ALE.2=FSMC_A17,21b-a3
SH.FSMC_A18.0=FSMC_A18,21b-a1
SH.FSMC_A18.1=FSMC_A18,21b-a2
SH.FSMC_A18.2=FSMC_A18,21b-a3
SH.FSMC_A19.0=FSMC_A19,21b-a1
SH.FSMC_A19.1=FSMC_A19,21b-a2
SH.FSMC_A19.2=FSMC_A19,21b-a3
SH.FSMC_A2.0=FSMC_A2,21b-a1
SH.FSMC_A2.1=FSMC_A2,21b-a2
SH.FSMC_A2.2=FSMC_A2,21b-a3
SH.FSMC_A20.0=FSMC_A20,21b-a1
SH.FSMC_A20.1=FSMC_A20,21b-a2
SH.FSMC_A20.2=FSMC_A20,21b-a3
SH.FSMC_A3.0=FSMC_A3,21b-a1
SH.FSMC_A3.1=FSMC_A3,21b-a2
SH.FSMC_A3.2=FSMC_A3,21b-a3
SH.FSMC_A4.0=FSMC_A4,21b-a1
SH.FSMC_A4.1=FSMC_A4,21b-a2
SH.FSMC_A4.2=FSMC_A4,21b-a3
SH.FSMC_A5.0=FSMC_A5,21b-a1
SH.FSMC_A5.1=FSMC_A5,21b-a2
SH.FSMC_A5.2=FSMC_A5,21b-a3
SH.FSMC_A6.0=FSMC_A6,21b-a1
SH.FSMC_A6.1=FSMC_A6,21b-a2
SH.FSMC_A6.2=FSMC_A6,21b-a3
SH.FSMC_A7.0=FSMC_A7,21b-a1
SH.FSMC_A7.1=FSMC_A7,21b-a2
SH.FSMC_A7.2=FSMC_A7,21b-a3
SH.FSMC_A8.0=FSMC_A8,21b-a1
SH.FSMC_A8.1=FSMC_A8,21b-a2
SH.FSMC_A8.2=FSMC_A8,21b-a3
SH.FSMC_A9.0=FSMC_A9,21b-a1
SH.FSMC_A9.1=FSMC_A9,21b-a2
SH.FSMC_A9.2=FSMC_A9,21b-a3
SH.FSMC_CLK.0=FSMC_CLK
SH.FSMC_D0_DA0.0=FSMC_D0,16b-d1
SH.FSMC_D0_DA0.1=FSMC_D0,16b-d2
SH.FSMC_D0_DA0.2=FSMC_D0,16b-d3
SH.FSMC_D10_DA10.0=FSMC_D10,16b-d1
SH.FSMC_D10_DA10.1=FSMC_D10,16b-d2
SH.FSMC_D10_DA10.2=FSMC_D10,16b-d3
SH.FSMC_D11_DA11.0=FSMC_D11,16b-d1
SH.FSMC_D11_DA11.1=FSMC_D11,16b-d2
SH.FSMC_D11_DA11.2=FSMC_D11,16b-d3
SH.FSMC_D12_DA12.0=FSMC_D12,16b-d1
SH.FSMC_D12_DA12.1=FSMC_D12,16b-d2
SH.FSMC_D12_DA12.2=FSMC_D12,16b-d3
SH.FSMC_D13_DA13.0=FSMC_D13,16b-d1
SH.FSMC_D13_DA13.1=FSMC_D13,16b-d2
SH.FSMC_D13_DA13.2=FSMC_D13,16b-d3
SH.FSMC_D14_DA14.0=FSMC_D14,16b-d1
SH.FSMC_D14_DA14.1=FSMC_D14,16b-d2
SH.FSMC_D14_DA14.2=FSMC_D14,16b-d3
SH.FSMC_D15_DA15.0=FSMC_D15,16b-d1
SH.FSMC_D15_DA15.1=FSMC_D15,16b-d2
SH.FSMC_D15_DA15.2=FSMC_D15,16b-d3
SH.FSMC_D1_DA1.0=FSMC_D1,16b-d1
SH.FSMC_D1_DA1.1=FSMC_D1,16b-d2
SH.FSMC_D1_DA1.2=FSMC_D1,16b-d3
SH.FSMC_D2_DA2.0=FSMC_D2,16b-d1
SH.FSMC_D2_DA2.1=FSMC_D2,16b-d2
SH.FSMC_D2_DA2.2=FSMC_D2,16b-d3
SH.FSMC_D3_DA3.0=FSMC_D3,16b-d1
SH.FSMC_D3_DA3.1=FSMC_D3,16b-d2
SH.FSMC_D3_DA3.2=FSMC_D3,16b-d3
SH.FSMC_D4_DA4.0=FSMC_D4,16b-d1
SH.FSMC_D4_DA4.1=FSMC_D4,16b-d2
SH.FSMC_D4_DA4.2=FSMC_D4,16b-d3
SH.FSMC_D5_DA5.0=FSMC_D5,16b-d1
SH.FSMC_D5_DA5.1=FSMC_D5,16b-d2
SH.FSMC_D5_DA5.2=FSMC_D5,16b-d3
SH.FSMC_D6_DA6.0=FSMC_D6,16b-d1
SH.FSMC_D6_DA6.1=FSMC_D6,16b-d2
SH.FSMC_D6_DA6.2=FSMC_D6,16b-d3
SH.FSMC_D7_DA7.0=FSMC_D7,16b-d1
SH.FSMC_D7_DA7.1=FSMC_D7,16b-d2
SH.FSMC_D7_DA7.2=FSMC_D7,16b-d3
SH.FSMC_D8_DA8.0=FSMC_D8,16b-d1
SH.FSMC_D8_DA8.1=FSMC_D8,16b-d2
SH.FSMC_D8_DA8.2=FSMC_D8,16b-d3
SH.FSMC_D9_DA9.0=FSMC_D9,16b-d1
SH.FSMC_D9_DA9.1=FSMC_D9,16b-d2
SH.FSMC_D9_DA9.2=FSMC_D9,16b-d3
SH.FSMC_NBL0.0=FSMC_NBL0,2ByteEnable2
SH.FSMC_NBL1.0=FSMC_NBL1,2ByteEnable2
SH.FSMC_NL.0=FSMC_NL
SH.FSMC_NOE.0=FSMC_NOE,NorFlash1
SH.FSMC_NOE.1=FSMC_NOE,Sram2
SH.FSMC_NOE.2=FSMC_NOE,Sram3
SH.FSMC_NWAIT.0=FSMC_NWAIT
SH.FSMC_NWE.0=FSMC_NWE,NorFlash1
SH.FSMC_NWE.1=FSMC_NWE,Sram2
SH.FSMC_NWE.2=FSMC_NWE,Sram3
TIM6.Period=0xFFF
TIM6.TIM_MasterOutputTrigger=TIM_TRGO_UPDATE
VP_FREERTOS_VS_ENABLE.Mode=Enabled
VP_LWIP_VS_Enabled.Mode=Enabled
VP_TIM6_VS_ClockSourceINT.Mode=Enable_Timer
board=STM3240G-EVAL

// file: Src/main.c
/**
 ******************************************************************************
 * File Name          : main.c
 * Description        : Main program body
 ******************************************************************************
 *
 * COPYRIGHT(c) 2016 STMicroelectronics
 *
 * Redistribution and use in source and binary forms, with or without modification,
 * are permitted provided that the following conditions are met:
 *   1. Redistributions of source code must retain the above copyright notice,
 *      this list of conditions and the following disclaimer.
 *   2. Redistributions in binary form must reproduce the above copyright notice,
 *      this list of conditions and the following disclaimer in the documentation
 *      and/or other materials provided with the distribution.
 *   3. Neither the name of STMicroelectronics nor the names of its contributors
 *      may be used to endorse or promote products derived from this software
 *      without specific prior written permission.
 *
 * THIS SOFTWARE IS PROVIDED BY THE COPYRIGHT HOLDERS AND CONTRIBUTORS "AS IS"
 * AND ANY EXPRESS OR IMPLIED WARRANTIES, INCLUDING, BUT NOT LIMITED TO, THE
 * IMPLIED WARRANTIES OF MERCHANTABILITY AND FITNESS FOR A PARTICULAR PURPOSE ARE
 * DISCLAIMED. IN NO EVENT SHALL THE COPYRIGHT HOLDER OR CONTRIBUTORS BE LIABLE
 * FOR ANY DIRECT, INDIRECT, INCIDENTAL, SPECIAL, EXEMPLARY, OR CONSEQUENTIAL
 * DAMAGES (INCLUDING, BUT NOT LIMITED TO, PROCUREMENT OF SUBSTITUTE GOODS OR
 * SERVICES; LOSS OF USE, DATA, OR PROFITS; OR BUSINESS INTERRUPTION) HOWEVER
 * CAUSED AND ON ANY THEORY OF LIABILITY, WHETHER IN CONTRACT, STRICT LIABILITY,
 * OR TORT (INCLUDING NEGLIGENCE OR OTHERWISE) ARISING IN ANY WAY OUT OF THE USE
 * OF THIS SOFTWARE, EVEN IF ADVISED OF THE POSSIBILITY OF SUCH DAMAGE.
 *
 ******************************************************************************
 */
#include "stm32f4xx_hal.h"
#include "cmsis_os.h"
#include "lwip.h"

/* USER CODE BEGIN Includes */
#include "battery-socket.h"
#include "arm_math.h"
#include "arm_common_tables.h"
/* USER CODE END Includes */

ADC_HandleTypeDef hadc1;
ADC_HandleTypeDef hadc2;
DMA_HandleTypeDef hdma_adc1;

DAC_HandleTypeDef hdac;
DMA_HandleTypeDef hdma_dac1;

DCMI_HandleTypeDef hdcmi;

I2C_HandleTypeDef hi2c1;

RTC_HandleTypeDef hrtc;

SD_HandleTypeDef hsd;
HAL_SD_CardInfoTypedef SDCardInfo;

TIM_HandleTypeDef htim6;

UART_HandleTypeDef huart3;

NOR_HandleTypeDef hnor1;
SRAM_HandleTypeDef hsram2;
SRAM_HandleTypeDef hsram3;
osThreadId defaultTaskHandle;

/* USER CODE BEGIN PV */
/* Private variables ---------------------------------------------------------*/
VoltageStruct voltageStruct;

/* Variable used to get converted value */
__IO uint32_t aADCDualConvertedValue[VOLTAGE_BUFFER_LENGTH] = { 0 };
__IO uint16_t uhADCxConvertedValue[VOLTAGE_BUFFER_LENGTH] = { 0 };
__IO uint16_t uhDACxConvertedValue = 0;
uint32_t sampleCounter = 0;
uint32_t sampleMultiplier = 0;
uint32_t bufferFirst[ETHERNET_BUFFER_LENGTH] = { 0 };
uint32_t bufferLast[ETHERNET_BUFFER_LENGTH] = { 0 };

#define sinBufferSize 1024
__IO uint16_t sinBuffer[sinBufferSize] = { 0 };

/* USER CODE END PV */

void SystemClock_Config(void);
static void MX_GPIO_Init(void);
static void MX_DMA_Init(void);
static void MX_ADC1_Init(void);
static void MX_ADC2_Init(void);
static void MX_DAC_Init(void);
static void MX_DCMI_Init(void);
static void MX_FSMC_Init(void);
static void MX_I2C1_Init(void);
static void MX_RTC_Init(void);
static void MX_SDIO_SD_Init(void);
static void MX_TIM6_Init(void);
static void MX_USART3_UART_Init(void);
static void MX_USB_OTG_FS_USB_Init(void);
void StartDefaultTask(void const * argument);

/* USER CODE BEGIN PFP */
/* Private function prototypes -----------------------------------------------*/
static void DAC_Ch1_SinConfig(void);
void processAdcPacket(uint32_t startIndex, uint32_t endIndex);

static void Error_Handler(void);
void HAL_ADC_ConvCpltCallback(ADC_HandleTypeDef* AdcHandle);

/* USER CODE END PFP */

int main(void) {

	/* USER CODE BEGIN 1 */
	voltageStruct.packetHeader = 0x0000AA55;
	voltageStruct.bufferFirstHalf = bufferFirst;
	voltageStruct.bufferLastHalf = bufferLast;
	voltageStruct.bufferLength = ETHERNET_BUFFER_LENGTH;

	/* USER CODE END 1 */

	/* MCU Configuration----------------------------------------------------------*/

	/* Reset of all peripherals, Initializes the Flash interface and the Systick. */
	HAL_Init();

	/* Configure the system clock */
	SystemClock_Config();

	/* Initialize all configured peripherals */
	MX_GPIO_Init();
	MX_DMA_Init();
	MX_ADC1_Init();
	MX_ADC2_Init();
	MX_DAC_Init();
	MX_DCMI_Init();
	MX_FSMC_Init();
	MX_I2C1_Init();
	MX_RTC_Init();
	MX_SDIO_SD_Init();
	MX_TIM6_Init();
	MX_USART3_UART_Init();
	MX_USB_OTG_FS_USB_Init();

	/* USER CODE BEGIN 2 */

	/*##-2- Enable TIM peripheral counter ######################################*/
	HAL_TIM_Base_Start(&htim6);

	/*## Enable peripherals ####################################################*/

	/* Enable ADC slave */
	if (HAL_ADC_Start(&hadc2) != HAL_OK) {
		/* Start Error */
		Error_Handler();
	}

	/*## Start ADC conversions #################################################*/

	/* Start ADCx and ADCy multimode conversion with interruption */
	if (HAL_ADCEx_MultiModeStart_DMA(&hadc1,
			(uint32_t *) &aADCDualConvertedValue, VOLTAGE_BUFFER_LENGTH)
			!= HAL_OK) {
		/* Start Error */
		Error_Handler();
	}

	DAC_Ch1_SinConfig();

	/* USER CODE END 2 */

	/* Create the thread(s) */
	/* definition and creation of defaultTask */
	osThreadDef(defaultTask, StartDefaultTask, osPriorityNormal, 0, 128);
	defaultTaskHandle = osThreadCreate(osThread(defaultTask), NULL);

	/* USER CODE BEGIN RTOS_THREADS */
	/* add threads, ... */

//  osThreadDef(LED4, ToggleLed4, osPriorityNormal, 0, configMINIMAL_STACK_SIZE);
//  osThreadCreate(osThread(LED4), NULL);
//  osThreadDef(BATTERYADC1, BatteryVoltageMonitor, osPriorityNormal, 0, configMINIMAL_STACK_SIZE);
//  osThreadCreate(osThread(BATTERYADC1), NULL);
//  osThreadDef(BATTERYDAC1, BatteryVoltageController, osPriorityNormal, 0, configMINIMAL_STACK_SIZE);
//  osThreadCreate(osThread(BATTERYDAC1), NULL);
	/* USER CODE END RTOS_THREADS */

	/* Start scheduler */
	osKernelStart();

	/* We should never get here as control is now taken by the scheduler */

	/* Infinite loop */
	while (1) {

	}

}

/** System Clock Configuration
 */
void SystemClock_Config(void) {

	RCC_OscInitTypeDef RCC_OscInitStruct;
	RCC_ClkInitTypeDef RCC_ClkInitStruct;
	RCC_PeriphCLKInitTypeDef PeriphClkInitStruct;

	__PWR_CLK_ENABLE()
	;

	__HAL_PWR_VOLTAGESCALING_CONFIG(PWR_REGULATOR_VOLTAGE_SCALE1);

	RCC_OscInitStruct.OscillatorType = RCC_OSCILLATORTYPE_LSI
			| RCC_OSCILLATORTYPE_HSE;
	RCC_OscInitStruct.HSEState = RCC_HSE_ON;
	RCC_OscInitStruct.LSIState = RCC_LSI_ON;
	RCC_OscInitStruct.PLL.PLLState = RCC_PLL_ON;
	RCC_OscInitStruct.PLL.PLLSource = RCC_PLLSOURCE_HSE;
	RCC_OscInitStruct.PLL.PLLM = 25;
	RCC_OscInitStruct.PLL.PLLN = 336;
	RCC_OscInitStruct.PLL.PLLP = RCC_PLLP_DIV2;
	RCC_OscInitStruct.PLL.PLLQ = 7;
	HAL_RCC_OscConfig(&RCC_OscInitStruct);

	RCC_ClkInitStruct.ClockType = RCC_CLOCKTYPE_SYSCLK | RCC_CLOCKTYPE_PCLK1
			| RCC_CLOCKTYPE_PCLK2;
	RCC_ClkInitStruct.SYSCLKSource = RCC_SYSCLKSOURCE_PLLCLK;
	RCC_ClkInitStruct.AHBCLKDivider = RCC_SYSCLK_DIV1;
	RCC_ClkInitStruct.APB1CLKDivider = RCC_HCLK_DIV4;
	RCC_ClkInitStruct.APB2CLKDivider = RCC_HCLK_DIV2;
	HAL_RCC_ClockConfig(&RCC_ClkInitStruct, FLASH_LATENCY_5);

	PeriphClkInitStruct.PeriphClockSelection = RCC_PERIPHCLK_RTC;
	PeriphClkInitStruct.RTCClockSelection = RCC_RTCCLKSOURCE_LSI;
	HAL_RCCEx_PeriphCLKConfig(&PeriphClkInitStruct);

	HAL_RCC_MCOConfig(RCC_MCO1, RCC_MCO1SOURCE_HSE, RCC_MCODIV_1);

	HAL_SYSTICK_Config(HAL_RCC_GetHCLKFreq() / 1000);

	HAL_SYSTICK_CLKSourceConfig(SYSTICK_CLKSOURCE_HCLK);

	/* SysTick_IRQn interrupt configuration */
	HAL_NVIC_SetPriority(SysTick_IRQn, 15, 0);
}

/* ADC1 init function */
void MX_ADC1_Init(void) {

	ADC_MultiModeTypeDef multimode;
	ADC_ChannelConfTypeDef sConfig;

	/**Configure the global features of the ADC (Clock, Resolution, Data Alignment and number of conversion)
	 */
	hadc1.Instance = ADC1;
	hadc1.Init.ClockPrescaler = ADC_CLOCKPRESCALER_PCLK_DIV4;
	hadc1.Init.Resolution = ADC_RESOLUTION12b;
	hadc1.Init.ScanConvMode = DISABLE;
	hadc1.Init.ContinuousConvMode = ENABLE;
	hadc1.Init.DiscontinuousConvMode = DISABLE;
	hadc1.Init.ExternalTrigConvEdge = ADC_EXTERNALTRIGCONVEDGE_NONE;
	hadc1.Init.DataAlign = ADC_DATAALIGN_RIGHT;
	hadc1.Init.NbrOfConversion = 1;
	hadc1.Init.DMAContinuousRequests = ENABLE;
	hadc1.Init.EOCSelection = EOC_SINGLE_CONV;
	HAL_ADC_Init(&hadc1);

	/**Configure the ADC multi-mode
	 */
	multimode.Mode = ADC_DUALMODE_REGSIMULT;
	multimode.DMAAccessMode = ADC_DMAACCESSMODE_2;
	multimode.TwoSamplingDelay = ADC_TWOSAMPLINGDELAY_5CYCLES;
	HAL_ADCEx_MultiModeConfigChannel(&hadc1, &multimode);

	/**Configure for the selected ADC regular channel its corresponding rank in the sequencer and its sample time.
	 */
	sConfig.Channel = ADC_CHANNEL_8;
	sConfig.Rank = 1;
	sConfig.SamplingTime = ADC_SAMPLETIME_15CYCLES;
	HAL_ADC_ConfigChannel(&hadc1, &sConfig);

}

/* ADC2 init function */
void MX_ADC2_Init(void) {

	ADC_MultiModeTypeDef multimode;
	ADC_ChannelConfTypeDef sConfig;

	/**Configure the global features of the ADC (Clock, Resolution, Data Alignment and number of conversion)
	 */
	hadc2.Instance = ADC2;
	hadc2.Init.ClockPrescaler = ADC_CLOCKPRESCALER_PCLK_DIV4;
	hadc2.Init.Resolution = ADC_RESOLUTION12b;
	hadc2.Init.ScanConvMode = DISABLE;
	hadc2.Init.ContinuousConvMode = ENABLE;
	hadc2.Init.DiscontinuousConvMode = DISABLE;
	hadc2.Init.DataAlign = ADC_DATAALIGN_RIGHT;
	hadc2.Init.NbrOfConversion = 1;
	hadc2.Init.DMAContinuousRequests = ENABLE;
	hadc2.Init.EOCSelection = EOC_SINGLE_CONV;
	HAL_ADC_Init(&hadc2);

	/**Configure the ADC multi-mode
	 */
	multimode.Mode = ADC_DUALMODE_REGSIMULT;
	multimode.DMAAccessMode = ADC_DMAACCESSMODE_2;
	multimode.TwoSamplingDelay = ADC_TWOSAMPLINGDELAY_5CYCLES;
	HAL_ADCEx_MultiModeConfigChannel(&hadc2, &multimode);

	/**Configure for the selected ADC regular channel its corresponding rank in the sequencer and its sample time.
	 */
	sConfig.Channel = ADC_CHANNEL_9;
	sConfig.Rank = 1;
	sConfig.SamplingTime = ADC_SAMPLETIME_15CYCLES;
	HAL_ADC_ConfigChannel(&hadc2, &sConfig);

}

/* DAC init function */
void MX_DAC_Init(void) {

	DAC_ChannelConfTypeDef sConfig;

	/**DAC Initialization
	 */
	hdac.Instance = DAC;
	HAL_DAC_Init(&hdac);

	/**DAC channel OUT1 config
	 */
	sConfig.DAC_Trigger = DAC_TRIGGER_T6_TRGO;
	sConfig.DAC_OutputBuffer = DAC_OUTPUTBUFFER_ENABLE;
	HAL_DAC_ConfigChannel(&hdac, &sConfig, DAC_CHANNEL_1);

}

/* DCMI init function */
void MX_DCMI_Init(void) {

	hdcmi.Instance = DCMI;
	hdcmi.Init.SynchroMode = DCMI_SYNCHRO_HARDWARE;
	hdcmi.Init.PCKPolarity = DCMI_PCKPOLARITY_FALLING;
	hdcmi.Init.VSPolarity = DCMI_VSPOLARITY_LOW;
	hdcmi.Init.HSPolarity = DCMI_HSPOLARITY_LOW;
	hdcmi.Init.CaptureRate = DCMI_CR_ALL_FRAME;
	hdcmi.Init.ExtendedDataMode = DCMI_EXTEND_DATA_8B;
	hdcmi.Init.JPEGMode = DCMI_JPEG_DISABLE;
	HAL_DCMI_Init(&hdcmi);

}

/* I2C1 init function */
void MX_I2C1_Init(void) {

	hi2c1.Instance = I2C1;
	hi2c1.Init.ClockSpeed = 100000;
	hi2c1.Init.DutyCycle = I2C_DUTYCYCLE_2;
	hi2c1.Init.OwnAddress1 = 0;
	hi2c1.Init.AddressingMode = I2C_ADDRESSINGMODE_7BIT;
	hi2c1.Init.DualAddressMode = I2C_DUALADDRESS_DISABLED;
	hi2c1.Init.OwnAddress2 = 0;
	hi2c1.Init.GeneralCallMode = I2C_GENERALCALL_DISABLED;
	hi2c1.Init.NoStretchMode = I2C_NOSTRETCH_DISABLED;
	HAL_I2C_Init(&hi2c1);

}

/* RTC init function */
void MX_RTC_Init(void) {

	RTC_TimeTypeDef sTime;
	RTC_DateTypeDef sDate;
	RTC_AlarmTypeDef sAlarm;

	/**Initialize RTC and set the Time and Date
	 */
	hrtc.Instance = RTC;
	hrtc.Init.HourFormat = RTC_HOURFORMAT_24;
	hrtc.Init.AsynchPrediv = 127;
	hrtc.Init.SynchPrediv = 255;
	hrtc.Init.OutPut = RTC_OUTPUT_ALARMA;
	hrtc.Init.OutPutPolarity = RTC_OUTPUT_POLARITY_HIGH;
	hrtc.Init.OutPutType = RTC_OUTPUT_TYPE_OPENDRAIN;
	HAL_RTC_Init(&hrtc);

	sTime.Hours = 0x0;
	sTime.Minutes = 0x0;
	sTime.Seconds = 0x0;
	sTime.DayLightSaving = RTC_DAYLIGHTSAVING_NONE;
	sTime.StoreOperation = RTC_STOREOPERATION_RESET;
	HAL_RTC_SetTime(&hrtc, &sTime, FORMAT_BCD);

	sDate.WeekDay = RTC_WEEKDAY_MONDAY;
	sDate.Month = RTC_MONTH_JANUARY;
	sDate.Date = 0x1;
	sDate.Year = 0x0;

	HAL_RTC_SetDate(&hrtc, &sDate, FORMAT_BCD);

	/**Enable the Alarm A
	 */
	sAlarm.AlarmTime.Hours = 0x0;
	sAlarm.AlarmTime.Minutes = 0x0;
	sAlarm.AlarmTime.Seconds = 0x0;
	sAlarm.AlarmTime.SubSeconds = 0x0;
	sAlarm.AlarmTime.DayLightSaving = RTC_DAYLIGHTSAVING_NONE;
	sAlarm.AlarmTime.StoreOperation = RTC_STOREOPERATION_RESET;
	sAlarm.AlarmMask = RTC_ALARMMASK_NONE;
	sAlarm.AlarmSubSecondMask = RTC_ALARMSUBSECONDMASK_ALL;
	sAlarm.AlarmDateWeekDaySel = RTC_ALARMDATEWEEKDAYSEL_DATE;
	sAlarm.AlarmDateWeekDay = 0x1;
	sAlarm.Alarm = RTC_ALARM_A;
	HAL_RTC_SetAlarm(&hrtc, &sAlarm, FORMAT_BCD);

}

/* SDIO init function */
void MX_SDIO_SD_Init(void) {

	hsd.Instance = SDIO;
	hsd.Init.ClockEdge = SDIO_CLOCK_EDGE_RISING;
	hsd.Init.ClockBypass = SDIO_CLOCK_BYPASS_DISABLE;
	hsd.Init.ClockPowerSave = SDIO_CLOCK_POWER_SAVE_DISABLE;
	hsd.Init.BusWide = SDIO_BUS_WIDE_1B;
	hsd.Init.HardwareFlowControl = SDIO_HARDWARE_FLOW_CONTROL_DISABLE;
	hsd.Init.ClockDiv = 0;
	HAL_SD_Init(&hsd, &SDCardInfo);

}

/* TIM6 init function */
void MX_TIM6_Init(void) {

	TIM_MasterConfigTypeDef sMasterConfig;

	htim6.Instance = TIM6;
	htim6.Init.Prescaler = 0;
	htim6.Init.CounterMode = TIM_COUNTERMODE_UP;
	htim6.Init.Period = 0xFFF;
	HAL_TIM_Base_Init(&htim6);

	sMasterConfig.MasterOutputTrigger = TIM_TRGO_UPDATE;
	sMasterConfig.MasterSlaveMode = TIM_MASTERSLAVEMODE_DISABLE;
	HAL_TIMEx_MasterConfigSynchronization(&htim6, &sMasterConfig);

}

/* USART3 init function */
void MX_USART3_UART_Init(void) {

	huart3.Instance = USART3;
	huart3.Init.BaudRate = 115200;
	huart3.Init.WordLength = UART_WORDLENGTH_8B;
	huart3.Init.StopBits = UART_STOPBITS_1;
	huart3.Init.Parity = UART_PARITY_NONE;
	huart3.Init.Mode = UART_MODE_TX_RX;
	huart3.Init.HwFlowCtl = UART_HWCONTROL_NONE;
	huart3.Init.OverSampling = UART_OVERSAMPLING_16;
	HAL_UART_Init(&huart3);

}

/* USB_OTG_FS init function */
void MX_USB_OTG_FS_USB_Init(void) {

}

void MX_DMA_Init(void) {
	/* DMA controller clock enable */
	__DMA1_CLK_ENABLE()
	;
	__DMA2_CLK_ENABLE()
	;

	/* DMA interrupt init */
	HAL_NVIC_SetPriority(DMA1_Stream5_IRQn, 5, 0);
	HAL_NVIC_EnableIRQ(DMA1_Stream5_IRQn);
	HAL_NVIC_SetPriority(DMA2_Stream0_IRQn, 5, 0);
	HAL_NVIC_EnableIRQ(DMA2_Stream0_IRQn);

}

/** Configure pins
 PE2   ------> SYS_TRACECLK
 PB5   ------> USB_OTG_HS_ULPI_D7
 PE5   ------> SYS_TRACED2
 PE6   ------> SYS_TRACED3
 PA12   ------> USB_OTG_FS_DP
 PI3   ------> I2S2_SD
 PA11   ------> USB_OTG_FS_DM
 PA10   ------> USB_OTG_FS_ID
 PI11   ------> USB_OTG_HS_ULPI_DIR
 PI0   ------> I2S2_WS
 PA9   ------> USB_OTG_FS_VBUS
 PA8   ------> RCC_MCO_1
 PH4   ------> USB_OTG_HS_ULPI_NXT
 PG7   ------> USART6_CK
 PF10   ------> ADC3_IN8
 PF9   ------> ADC3_IN7
 PC0   ------> USB_OTG_HS_ULPI_STP
 PA5   ------> USB_OTG_HS_ULPI_CK
 PB12   ------> USB_OTG_HS_ULPI_D5
 PB13   ------> USB_OTG_HS_ULPI_D6
 PB10   ------> USB_OTG_HS_ULPI_D3
 PB11   ------> USB_OTG_HS_ULPI_D4
 */
void MX_GPIO_Init(void) {

	GPIO_InitTypeDef GPIO_InitStruct;

	/* GPIO Ports Clock Enable */
	__GPIOE_CLK_ENABLE()
	;
	__GPIOB_CLK_ENABLE()
	;
	__GPIOG_CLK_ENABLE()
	;
	__GPIOD_CLK_ENABLE()
	;
	__GPIOC_CLK_ENABLE()
	;
	__GPIOA_CLK_ENABLE()
	;
	__GPIOI_CLK_ENABLE()
	;
	__GPIOH_CLK_ENABLE()
	;
	__GPIOF_CLK_ENABLE()
	;

	/*Configure GPIO pins : TRACE_CLK_Pin TRACE_D2_Pin TRACE_D3_Pin */
	GPIO_InitStruct.Pin = TRACE_CLK_Pin | TRACE_D2_Pin | TRACE_D3_Pin;
	GPIO_InitStruct.Mode = GPIO_MODE_AF_PP;
	GPIO_InitStruct.Pull = GPIO_NOPULL;
	GPIO_InitStruct.Speed = GPIO_SPEED_LOW;
	GPIO_InitStruct.Alternate = GPIO_AF0_TRACE;
	HAL_GPIO_Init(GPIOE, &GPIO_InitStruct);

	/*Configure GPIO pins : ULPI_D7_Pin ULPI_D5_Pin ULPI_D6_Pin ULPI_D3_Pin
	 ULPI_D4_Pin */
	GPIO_InitStruct.Pin = ULPI_D7_Pin | ULPI_D5_Pin | ULPI_D6_Pin | ULPI_D3_Pin
			| ULPI_D4_Pin;
	GPIO_InitStruct.Mode = GPIO_MODE_AF_PP;
	GPIO_InitStruct.Pull = GPIO_NOPULL;
	GPIO_InitStruct.Speed = GPIO_SPEED_HIGH;
	GPIO_InitStruct.Alternate = GPIO_AF10_OTG_HS;
	HAL_GPIO_Init(GPIOB, &GPIO_InitStruct);

	/*Configure GPIO pin : User_Button_Pin */
	GPIO_InitStruct.Pin = User_Button_Pin;
	GPIO_InitStruct.Mode = GPIO_MODE_EVT_RISING;
	GPIO_InitStruct.Pull = GPIO_NOPULL;
	HAL_GPIO_Init(User_Button_GPIO_Port, &GPIO_InitStruct);

	/*Configure GPIO pins : SmartCard_CMDVCC_Pin LED2_Pin LED1_Pin */
	GPIO_InitStruct.Pin = SmartCard_CMDVCC_Pin | LED2_Pin | LED1_Pin;
	GPIO_InitStruct.Mode = GPIO_MODE_OUTPUT_PP;
	GPIO_InitStruct.Pull = GPIO_NOPULL;
	GPIO_InitStruct.Speed = GPIO_SPEED_LOW;
	HAL_GPIO_Init(GPIOG, &GPIO_InitStruct);

	/*Configure GPIO pins : USB_FS_DP_Pin USB_FS_DM_Pin USB_FS_ID_Pin */
	GPIO_InitStruct.Pin = USB_FS_DP_Pin | USB_FS_DM_Pin | USB_FS_ID_Pin;
	GPIO_InitStruct.Mode = GPIO_MODE_AF_PP;
	GPIO_InitStruct.Pull = GPIO_NOPULL;
	GPIO_InitStruct.Speed = GPIO_SPEED_LOW;
	GPIO_InitStruct.Alternate = GPIO_AF10_OTG_FS;
	HAL_GPIO_Init(GPIOA, &GPIO_InitStruct);

	/*Configure GPIO pins : I2S_SD_Pin I2S_WS_Pin */
	GPIO_InitStruct.Pin = I2S_SD_Pin | I2S_WS_Pin;
	GPIO_InitStruct.Mode = GPIO_MODE_AF_PP;
	GPIO_InitStruct.Pull = GPIO_NOPULL;
	GPIO_InitStruct.Speed = GPIO_SPEED_LOW;
	GPIO_InitStruct.Alternate = GPIO_AF5_SPI2;
	HAL_GPIO_Init(GPIOI, &GPIO_InitStruct);

	/*Configure GPIO pin : IO_Expander_INT_Pin */
	GPIO_InitStruct.Pin = IO_Expander_INT_Pin;
	GPIO_InitStruct.Mode = GPIO_MODE_EVT_RISING;
	GPIO_InitStruct.Pull = GPIO_NOPULL;
	HAL_GPIO_Init(IO_Expander_INT_GPIO_Port, &GPIO_InitStruct);

	/*Configure GPIO pin : LED3_Pin */
	GPIO_InitStruct.Pin = LED3_Pin;
	GPIO_InitStruct.Mode = GPIO_MODE_OUTPUT_PP;
	GPIO_InitStruct.Pull = GPIO_NOPULL;
	GPIO_InitStruct.Speed = GPIO_SPEED_LOW;
	HAL_GPIO_Init(LED3_GPIO_Port, &GPIO_InitStruct);

	/*Configure GPIO pins : SmartCard_3_5V_Pin OTG_FS_PowerSwitchOn_Pin */
	GPIO_InitStruct.Pin = SmartCard_3_5V_Pin | OTG_FS_PowerSwitchOn_Pin;
	GPIO_InitStruct.Mode = GPIO_MODE_OUTPUT_PP;
	GPIO_InitStruct.Pull = GPIO_NOPULL;
	GPIO_InitStruct.Speed = GPIO_SPEED_LOW;
	HAL_GPIO_Init(GPIOH, &GPIO_InitStruct);

	/*Configure GPIO pin : ULPI_DIR_Pin */
	GPIO_InitStruct.Pin = ULPI_DIR_Pin;
	GPIO_InitStruct.Mode = GPIO_MODE_AF_PP;
	GPIO_InitStruct.Pull = GPIO_NOPULL;
	GPIO_InitStruct.Speed = GPIO_SPEED_HIGH;
	GPIO_InitStruct.Alternate = GPIO_AF10_OTG_HS;
	HAL_GPIO_Init(ULPI_DIR_GPIO_Port, &GPIO_InitStruct);

	/*Configure GPIO pin : MicroSDCard_Detect_Pin */
	GPIO_InitStruct.Pin = MicroSDCard_Detect_Pin;
	GPIO_InitStruct.Mode = GPIO_MODE_INPUT;
	GPIO_InitStruct.Pull = GPIO_PULLUP;
	HAL_GPIO_Init(MicroSDCard_Detect_GPIO_Port, &GPIO_InitStruct);

	/*Configure GPIO pin : VBUS_FS_Pin */
	GPIO_InitStruct.Pin = VBUS_FS_Pin;
	GPIO_InitStruct.Mode = GPIO_MODE_INPUT;
	GPIO_InitStruct.Pull = GPIO_NOPULL;
	HAL_GPIO_Init(VBUS_FS_GPIO_Port, &GPIO_InitStruct);

//  /*Configure GPIO pin : MCO_Pin */
//  GPIO_InitStruct.Pin = MCO_Pin;
//  GPIO_InitStruct.Mode = GPIO_MODE_AF_PP;
//  GPIO_InitStruct.Pull = GPIO_NOPULL;
//  GPIO_InitStruct.Speed = GPIO_SPEED_LOW;
//  GPIO_InitStruct.Alternate = GPIO_AF0_MCO;
//  HAL_GPIO_Init(MCO_GPIO_Port, &GPIO_InitStruct);

	/*Configure GPIO pin : LED4_Pin */
	GPIO_InitStruct.Pin = LED4_Pin;
	GPIO_InitStruct.Mode = GPIO_MODE_OUTPUT_PP;
	GPIO_InitStruct.Pull = GPIO_NOPULL;
	GPIO_InitStruct.Speed = GPIO_SPEED_LOW;
	HAL_GPIO_Init(LED4_GPIO_Port, &GPIO_InitStruct);

	/*Configure GPIO pin : ULPI_NXT_Pin */
	GPIO_InitStruct.Pin = ULPI_NXT_Pin;
	GPIO_InitStruct.Mode = GPIO_MODE_AF_PP;
	GPIO_InitStruct.Pull = GPIO_NOPULL;
	GPIO_InitStruct.Speed = GPIO_SPEED_HIGH;
	GPIO_InitStruct.Alternate = GPIO_AF10_OTG_HS;
	HAL_GPIO_Init(ULPI_NXT_GPIO_Port, &GPIO_InitStruct);

	/*Configure GPIO pin : SmartCard_CLK_Pin */
	GPIO_InitStruct.Pin = SmartCard_CLK_Pin;
	GPIO_InitStruct.Mode = GPIO_MODE_AF_PP;
	GPIO_InitStruct.Pull = GPIO_NOPULL;
	GPIO_InitStruct.Speed = GPIO_SPEED_LOW;
	GPIO_InitStruct.Alternate = GPIO_AF8_USART6;
	HAL_GPIO_Init(SmartCard_CLK_GPIO_Port, &GPIO_InitStruct);

	/*Configure GPIO pin : SmartCard_RST_Pin */
	GPIO_InitStruct.Pin = SmartCard_RST_Pin;
	GPIO_InitStruct.Mode = GPIO_MODE_OUTPUT_PP;
	GPIO_InitStruct.Pull = GPIO_NOPULL;
	GPIO_InitStruct.Speed = GPIO_SPEED_LOW;
	HAL_GPIO_Init(SmartCard_RST_GPIO_Port, &GPIO_InitStruct);

	/*Configure GPIO pin : SmartCard_OFF_Pin */
	GPIO_InitStruct.Pin = SmartCard_OFF_Pin;
	GPIO_InitStruct.Mode = GPIO_MODE_INPUT;
	GPIO_InitStruct.Pull = GPIO_NOPULL;
	HAL_GPIO_Init(SmartCard_OFF_GPIO_Port, &GPIO_InitStruct);

	/*Configure GPIO pins : Audio_IN_Pin Potentiometer_Pin */
	GPIO_InitStruct.Pin = Audio_IN_Pin | Potentiometer_Pin;
	GPIO_InitStruct.Mode = GPIO_MODE_ANALOG;
	GPIO_InitStruct.Pull = GPIO_NOPULL;
	HAL_GPIO_Init(GPIOF, &GPIO_InitStruct);

	/*Configure GPIO pin : ULPI_STP_Pin */
	GPIO_InitStruct.Pin = ULPI_STP_Pin;
	GPIO_InitStruct.Mode = GPIO_MODE_AF_PP;
	GPIO_InitStruct.Pull = GPIO_NOPULL;
	GPIO_InitStruct.Speed = GPIO_SPEED_HIGH;
	GPIO_InitStruct.Alternate = GPIO_AF10_OTG_HS;
	HAL_GPIO_Init(ULPI_STP_GPIO_Port, &GPIO_InitStruct);

	/*Configure GPIO pin : SW1_Pin */
	GPIO_InitStruct.Pin = SW1_Pin;
	GPIO_InitStruct.Mode = GPIO_MODE_INPUT;
	GPIO_InitStruct.Pull = GPIO_NOPULL;
	HAL_GPIO_Init(SW1_GPIO_Port, &GPIO_InitStruct);

	/*Configure GPIO pin : ULPI_CLK_Pin */
	GPIO_InitStruct.Pin = ULPI_CLK_Pin;
	GPIO_InitStruct.Mode = GPIO_MODE_AF_PP;
	GPIO_InitStruct.Pull = GPIO_NOPULL;
	GPIO_InitStruct.Speed = GPIO_SPEED_HIGH;
	GPIO_InitStruct.Alternate = GPIO_AF10_OTG_HS;
	HAL_GPIO_Init(ULPI_CLK_GPIO_Port, &GPIO_InitStruct);

	/*Configure GPIO pin : PF11 */
	GPIO_InitStruct.Pin = GPIO_PIN_11;
	GPIO_InitStruct.Mode = GPIO_MODE_IT_RISING;
	GPIO_InitStruct.Pull = GPIO_NOPULL;
	HAL_GPIO_Init(GPIOF, &GPIO_InitStruct);

	/*Configure GPIO pin : MII_INT_Pin */
	GPIO_InitStruct.Pin = MII_INT_Pin;
	GPIO_InitStruct.Mode = GPIO_MODE_EVT_RISING;
	GPIO_InitStruct.Pull = GPIO_NOPULL;
	HAL_GPIO_Init(MII_INT_GPIO_Port, &GPIO_InitStruct);

}

/* FSMC initialization function */
void MX_FSMC_Init(void) {
	FSMC_NORSRAM_TimingTypeDef Timing;

	/** Perform the NOR1 memory initialization sequence
	 */
	hnor1.Instance = FSMC_NORSRAM_DEVICE;
	hnor1.Extended = FSMC_NORSRAM_EXTENDED_DEVICE;
	/* hnor1.Init */
	hnor1.Init.NSBank = FSMC_NORSRAM_BANK1;
	hnor1.Init.DataAddressMux = FSMC_DATA_ADDRESS_MUX_DISABLE;
	hnor1.Init.MemoryType = FSMC_MEMORY_TYPE_NOR;
	hnor1.Init.MemoryDataWidth = FSMC_NORSRAM_MEM_BUS_WIDTH_16;
	hnor1.Init.BurstAccessMode = FSMC_BURST_ACCESS_MODE_DISABLE;
	hnor1.Init.WaitSignalPolarity = FSMC_WAIT_SIGNAL_POLARITY_LOW;
	hnor1.Init.WrapMode = FSMC_WRAP_MODE_DISABLE;
	hnor1.Init.WaitSignalActive = FSMC_WAIT_TIMING_BEFORE_WS;
	hnor1.Init.WriteOperation = FSMC_WRITE_OPERATION_DISABLE;
	hnor1.Init.WaitSignal = FSMC_WAIT_SIGNAL_DISABLE;
	hnor1.Init.ExtendedMode = FSMC_EXTENDED_MODE_DISABLE;
	hnor1.Init.AsynchronousWait = FSMC_ASYNCHRONOUS_WAIT_DISABLE;
	hnor1.Init.WriteBurst = FSMC_WRITE_BURST_DISABLE;
	/* Timing */
	Timing.AddressSetupTime = 15;
	Timing.AddressHoldTime = 15;
	Timing.DataSetupTime = 255;
	Timing.BusTurnAroundDuration = 15;
	Timing.CLKDivision = 16;
	Timing.DataLatency = 17;
	Timing.AccessMode = FSMC_ACCESS_MODE_A;
	/* ExtTiming */

	HAL_NOR_Init(&hnor1, &Timing, NULL);

	/** Perform the SRAM2 memory initialization sequence
	 */
	hsram2.Instance = FSMC_NORSRAM_DEVICE;
	hsram2.Extended = FSMC_NORSRAM_EXTENDED_DEVICE;
	/* hsram2.Init */
	hsram2.Init.NSBank = FSMC_NORSRAM_BANK2;
	hsram2.Init.DataAddressMux = FSMC_DATA_ADDRESS_MUX_DISABLE;
	hsram2.Init.MemoryType = FSMC_MEMORY_TYPE_SRAM;
	hsram2.Init.MemoryDataWidth = FSMC_NORSRAM_MEM_BUS_WIDTH_16;
	hsram2.Init.BurstAccessMode = FSMC_BURST_ACCESS_MODE_DISABLE;
	hsram2.Init.WaitSignalPolarity = FSMC_WAIT_SIGNAL_POLARITY_LOW;
	hsram2.Init.WrapMode = FSMC_WRAP_MODE_DISABLE;
	hsram2.Init.WaitSignalActive = FSMC_WAIT_TIMING_BEFORE_WS;
	hsram2.Init.WriteOperation = FSMC_WRITE_OPERATION_DISABLE;
	hsram2.Init.WaitSignal = FSMC_WAIT_SIGNAL_DISABLE;
	hsram2.Init.ExtendedMode = FSMC_EXTENDED_MODE_DISABLE;
	hsram2.Init.AsynchronousWait = FSMC_ASYNCHRONOUS_WAIT_DISABLE;
	hsram2.Init.WriteBurst = FSMC_WRITE_BURST_DISABLE;
	/* Timing */
	Timing.AddressSetupTime = 15;
	Timing.AddressHoldTime = 15;
	Timing.DataSetupTime = 255;
	Timing.BusTurnAroundDuration = 15;
	Timing.CLKDivision = 16;
	Timing.DataLatency = 17;
	Timing.AccessMode = FSMC_ACCESS_MODE_A;
	/* ExtTiming */

	HAL_SRAM_Init(&hsram2, &Timing, NULL);

	/** Perform the SRAM3 memory initialization sequence
	 */
	hsram3.Instance = FSMC_NORSRAM_DEVICE;
	hsram3.Extended = FSMC_NORSRAM_EXTENDED_DEVICE;
	/* hsram3.Init */
	hsram3.Init.NSBank = FSMC_NORSRAM_BANK3;
	hsram3.Init.DataAddressMux = FSMC_DATA_ADDRESS_MUX_DISABLE;
	hsram3.Init.MemoryType = FSMC_MEMORY_TYPE_SRAM;
	hsram3.Init.MemoryDataWidth = FSMC_NORSRAM_MEM_BUS_WIDTH_16;
	hsram3.Init.BurstAccessMode = FSMC_BURST_ACCESS_MODE_DISABLE;
	hsram3.Init.WaitSignalPolarity = FSMC_WAIT_SIGNAL_POLARITY_LOW;
	hsram3.Init.WrapMode = FSMC_WRAP_MODE_DISABLE;
	hsram3.Init.WaitSignalActive = FSMC_WAIT_TIMING_BEFORE_WS;
	hsram3.Init.WriteOperation = FSMC_WRITE_OPERATION_DISABLE;
	hsram3.Init.WaitSignal = FSMC_WAIT_SIGNAL_DISABLE;
	hsram3.Init.ExtendedMode = FSMC_EXTENDED_MODE_DISABLE;
	hsram3.Init.AsynchronousWait = FSMC_ASYNCHRONOUS_WAIT_DISABLE;
	hsram3.Init.WriteBurst = FSMC_WRITE_BURST_DISABLE;
	/* Timing */
	Timing.AddressSetupTime = 15;
	Timing.AddressHoldTime = 15;
	Timing.DataSetupTime = 255;
	Timing.BusTurnAroundDuration = 15;
	Timing.CLKDivision = 16;
	Timing.DataLatency = 17;
	Timing.AccessMode = FSMC_ACCESS_MODE_A;
	/* ExtTiming */

	HAL_SRAM_Init(&hsram3, &Timing, NULL);

}

/* USER CODE BEGIN 4 */

//uint32_t dacCounter = 0;
//float32_t dacPeriod= 0x7FF / 50000000.;
//float32_t dacResolution = 2^12;
/////**
////  * @brief  Conversion complete callback in non blocking mode for Channel1
////  * @param  hdac: pointer to a DAC_HandleTypeDef structure that contains
////  *         the configuration information for the specified DAC.
////  * @retval None
////  */
//void HAL_DAC_ConvCpltCallbackCh1(DAC_HandleTypeDef* hdac)
//{
//  float32_t theta = dacCounter * 2. * 3.14 * dacPeriod;
//  uint32_t sinTheta = dacResolution * (1.001 + arm_sin_f32(theta)) / 2.;
//
////  uhDACxConvertedValue = (uint32_t)sinTheta;
//  dacCounter += 1;
////  HAL_DAC_SetValue(hdac, DAC_CHANNEL_1, DAC_ALIGN_8B_R, 2048);
//}
/**
 * @brief  Period elapsed callback in non blocking mode
 * @param  htim: TIM handle
 * @retval None
 */
void HAL_TIM_PeriodElapsedCallback(TIM_HandleTypeDef *htim) {
//	broadcastVoltageAll();
	HAL_GPIO_TogglePin(GPIOD, GPIO_PIN_12);
}

/**
 * @brief  Conversion complete callback in non blocking mode for Channel1
 * @param  hdac: pointer to a DAC_HandleTypeDef structure that contains
 *         the configuration information for the specified DAC.
 * @retval None
 */
//void HAL_DAC_ConvCpltCallbackCh1(DAC_HandleTypeDef* hdac)
//{
//	q15_t phase = 10 * HAL_GetTick() / 1000;
//	waveformValue = arm_sin_q15(phase);
//	HAL_DAC_SetValue(hdac, DAC_CHANNEL_1, DAC_ALIGN_12B_R, waveformValue);
//	HAL_DAC_Start(hdac, DAC_CHANNEL_1);
//	waveformValue = HAL_GetTick() % 4095;
//	if(HAL_DAC_Start_DMA(hdac, DAC_CHANNEL_1, (uint32_t*)&waveformValue, sizeof(uint16_t), DAC_ALIGN_12B_R) != HAL_OK)
//	{
//	/* Start Error */
//	Error_Handler();
//	}
//}
/**
 * @brief  This function is executed in case of error occurrence.
 * @param  None
 * @retval None
 */
static void Error_Handler(void) {
	/* Turn LED5 on */
//  BSP_LED_On(LED5);
	while (1) {
	}
}

int i, firstHalfBufferIsActive = 1;
uint32_t tick = 0;
/**
 * @brief  Conversion complete callback in non blocking mode
 * @param  AdcHandle : AdcHandle handle
 * @note   This example shows a simple way to report end of conversion, and
 *         you can add your own implementation.
 * @retval None
 */
void HAL_ADC_ConvCpltCallback(ADC_HandleTypeDef* AdcHandle) {
	int startIndex = VOLTAGE_BUFFER_LENGTH / 2;
	int endIndex = VOLTAGE_BUFFER_LENGTH;
	processAdcPacket(startIndex, endIndex);
}

void HAL_ADC_ConvHalfCpltCallback(ADC_HandleTypeDef* AdcHandle) {
	int startIndex = 0;
	int endIndex = VOLTAGE_BUFFER_LENGTH / 2;
	processAdcPacket(startIndex, endIndex);
}

void processAdcPacket(uint32_t startIndex, uint32_t endIndex) {
	uint32_t j, masterConvertedValue = 0, slaveConvertedValue = 0;

	for (j = startIndex; j < endIndex; j++) {
		masterConvertedValue += aADCDualConvertedValue[j] & 0xFFFF;
		slaveConvertedValue += aADCDualConvertedValue[j] >> 16;
	}

	if (firstHalfBufferIsActive) {
		voltageStruct.bufferFirstHalf[i] = voltageStruct.packetHeader;
		voltageStruct.bufferFirstHalf[i + 1] = tick;
		voltageStruct.bufferFirstHalf[i + 2] = masterConvertedValue
				/ (VOLTAGE_BUFFER_LENGTH / 2);
		voltageStruct.bufferFirstHalf[i + 3] = slaveConvertedValue
				/ (VOLTAGE_BUFFER_LENGTH / 2);
	} else {
		voltageStruct.bufferLastHalf[i] = voltageStruct.packetHeader;
		voltageStruct.bufferLastHalf[i + 1] = tick;
		voltageStruct.bufferLastHalf[i + 2] = masterConvertedValue
				/ (VOLTAGE_BUFFER_LENGTH / 2);
		voltageStruct.bufferLastHalf[i + 3] = slaveConvertedValue
				/ (VOLTAGE_BUFFER_LENGTH / 2);
	}
	tick += 1;

	if (i < ETHERNET_BUFFER_LENGTH - SINGLE_PACKET_LENGTH) {
		i += SINGLE_PACKET_LENGTH;
	} else {
		i = 0;
		firstHalfBufferIsActive = !firstHalfBufferIsActive;
	}

}

/**
 * @brief  Error DAC callback for Channel1.
 * @param  hdac: pointer to a DAC_HandleTypeDef structure that contains
 *         the configuration information for the specified DAC.
 * @retval None
 */
void HAL_DAC_ErrorCallbackCh1(DAC_HandleTypeDef *hdac) {
	Error_Handler();
}

/**
 * @brief  DMA underrun DAC callback for channel1.
 * @param  hdac: pointer to a DAC_HandleTypeDef structure that contains
 *         the configuration information for the specified DAC.
 * @retval None
 */
void HAL_DAC_DMAUnderrunCallbackCh1(DAC_HandleTypeDef *hdac) {
	Error_Handler();
}

#define PERIOD 2520
static void DAC_Ch1_SinConfig(void) {
	float32_t phase, sin, cos;

	uint16_t waveformValue;

	int i;
	for (i = 0; i < sinBufferSize; i++) {
		phase = ((float32_t) i) * 2. * 3.14 / ((float32_t) sinBufferSize);
		sin = arm_sin_f32(phase * 10.0);
		cos = arm_cos_f32(phase);

		waveformValue = 4095. * (2. + .3 * sin + cos) / 4.;
		sinBuffer[i] = waveformValue;
	}

	/*##-2- Enable DAC selected channel and associated DMA #############################*/
	if (HAL_DAC_Start_DMA(&hdac, DAC_CHANNEL_1, (uint32_t *) sinBuffer,
			(size_t) sinBufferSize, DAC_ALIGN_12B_R) != HAL_OK) {
		/* Start DMA Error */
		Error_Handler();
	}
}
/* USER CODE END 4 */

/* StartDefaultTask function */
void StartDefaultTask(void const * argument) {
	/* init code for LWIP */
	MX_LWIP_Init();

	/* USER CODE BEGIN 5 */

	voltage_server_socket();

	/* USER CODE END 5 */
}

/************************ (C) COPYRIGHT STMicroelectronics *****END OF FILE****/
